VERSION "Version"

NS_ :

BS_:

BU_: Tester CCU ADC CCU_CCURT1 CCU_CCURT2 RLR RRR ZCUF ZCUL ZCUR ZCUT EMS IDM DCDC IPS NIDU NIDUF DCUR OBC OPC LPC CPC EMCM GCU DCUF IPU BMS EOPF EOPR EVCC DCDC2 EDL SRS ECS EPS EPB RBM IBCS ICM IID IDC PHUDD AMP WHUD IMR INU IFC FAPA PAS PCS SCMR SCMRL SCMRR HVSMR SCMRM MFS WSM DRM IDU FCP LBMSAD AVAS ATSS DLPFL FBLCM FLISD FLLCM FRLCM RLLCMA RLLCMB RRLCMA RRLCMB RLISD DLPML DLPMR TRM PSDL PSDR HVSPRL HVSPRR RFR SBM WCM ETC TBOX2 TBOX IDUR CBM PLGM TMC LPC2 SCMT RCP RRISD LBMS RLBMS CCURT1 CCURT2 RT1_C1 RT2_C3 RT1_C0 OTAWL RAS EBB RCICP WCMFR WCMRL SAS CD

BO_ 704 CCU_IPS_1: 64 CCU
 SG_ IPS_1_CRC : 7|16@0+ (1,0) [0|65535] ""  BMS,ADC
 SG_ IPS_1_Counter : 23|8@0+ (1,0) [0|255] ""  BMS,ADC
 SG_ IPS_DCDCModeSt : 39|3@0+ (1,0) [0|7] ""  ADC

BO_ 794 CCU_LBMSAD_1: 64 CCU
 SG_ LBMSAD_1_CRC : 7|16@0+ (1,0) [0|65535] ""  ADC,LBMS
 SG_ LBMSAD_1_Counter : 23|8@0+ (1,0) [0|255] ""  ADC,LBMS
 SG_ LBMSAD_SOFVD : 28|1@0+ (1,0) [0|1] ""  ADC,LBMS
 SG_ LBMSAD_SOFEN : 30|2@0+ (1,0) [0|3] ""  ADC,LBMS

BO_ 958 CCU_TMC_4_New: 64 CCU
 SG_ HVACPmp_MotWPSt : 401|2@0+ (1,0) [0|3] ""  ZCUL,EMS,NIDU,DCUR,DCUF,IPU,BMS,IDC,ADC
 SG_ HVACPmp_MotWPErrCode : 415|20@0+ (1,0) [0|1048576] ""  NIDU,DCUR,DCUF,IPU,ADC
 SG_ HVACSns_MotorInTVD : 402|1@0+ (1,0) [0|1] ""  ZCUL,EMS,NIDU,DCUR,DCUF,IPU,BMS,IDC,ADC
 SG_ HVACSns_MotorInT : 427|9@0+ (0.5,-50) [-50|200] "degC"  ZCUL,EMS,NIDU,DCUR,DCUF,IPU,BMS,IDC,ADC
 SG_ HVACPmp_MotWPActDuty : 447|8@0+ (1,0) [0|100] "%"  ZCUL,NIDU,DCUR,DCUF,IPU,IDC,ADC

BO_ 709 TMS_5_New: 32 CCU_CCURT1
 SG_ HVAC_AutoFogFlt : 26|1@0+ (1,0) [0|1] ""  ADC
 SG_ HVAC_AutoFogSts : 27|1@0+ (1,0) [0|1] ""  ADC
 SG_ HVAC_CorrectedCabinTemp : 39|8@0+ (0.5,-40) [-40|87.5] "°C"  CCURT2,RT2_C3,TMC,ZCUL,ZCUR,IDC,ADC
 SG_ HVAC_CorrectedCabinTempVD : 28|1@0+ (1,0) [0|1] ""  CCURT2,RT2_C3,TMC,ZCUL,ZCUR,IDC,ADC
 SG_ HVAC_CorrectedExterTemp : 47|8@0+ (0.5,-40) [-40|87.5] "°C"  CCURT2,RT2_C3,OTAWL,TMC,ZCUL,ZCUR,EMS,IPS,NIDU,NIDUF,DCUR,OBC,GCU,DCUF,IPU,BMS,ECS,IBCS,IID,IDC,AMP,ADC,IFC,PAS,WSM
 SG_ HVAC_CorrectedExterTempFault : 30|2@0+ (1,0) [0|3] ""  CCURT2,RT2_C3,OTAWL,TMC,ZCUL,ZCUR,EMS,IPS,NIDU,NIDUF,DCUR,OBC,GCU,DCUF,IPU,BMS,ECS,IBCS,IID,IDC,AMP,ADC,IFC,PAS,WSM
 SG_ HVAC_CorrectedExterTempVD : 31|1@0+ (1,0) [0|1] ""  CCURT2,RT2_C3,OTAWL,TMC,ZCUL,ZCUR,EMS,IPS,NIDU,NIDUF,DCUR,OBC,GCU,DCUF,IPU,BMS,ECS,IBCS,IID,IDC,AMP,ADC,IFC,PAS,WSM
 SG_ HVAC_MotWtrPmpSt : 51|2@0+ (1,0) [0|3] ""  TMC,ZCUL,ZCUR,EMS,NIDU,NIDUF,DCUR,DCUF,IPU,IDC,ADC,FCP
 SG_ HVAC_RearDefrostSt : 116|1@0+ (1,0) [0|1] ""  ZCUL,ZCUR,IDC,RCICP,AMP,ADC,IFC,FCP,RCP,HVSPRL,HVSPRR
 SG_ HVAC_WindExitMode : 122|3@0+ (1,0) [0|7] ""  ZCUL,ZCUR,EMS,IDC,ADC,IFC

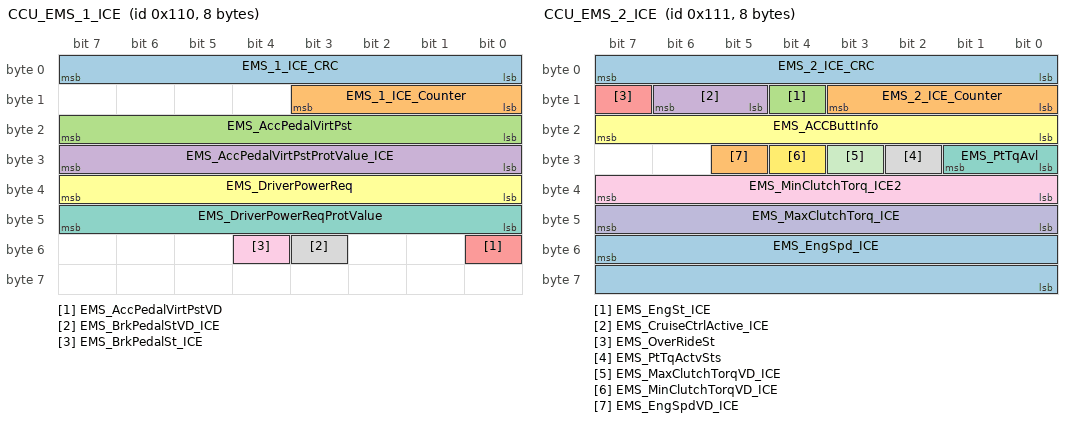
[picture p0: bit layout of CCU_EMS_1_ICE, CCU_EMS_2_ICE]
BO_ 272 CCU_EMS_1_ICE: 8 CCU
 SG_ EMS_1_ICE_CRC : 7|8@0+ (1,0) [0|255] ""  ADC
 SG_ EMS_1_ICE_Counter : 11|4@0+ (1,0) [0|14] ""  ADC
 SG_ EMS_AccPedalVirtPst : 23|8@0+ (0.392,0) [0|99.96] "%"  ADC
 SG_ EMS_AccPedalVirtPstProtValue_ICE : 31|8@0+ (1,0) [0|255] ""  ADC
 SG_ EMS_AccPedalVirtPstVD : 48|1@0+ (1,0) [0|1] ""  ADC
 SG_ EMS_DriverPowerReq : 39|8@0+ (0.78125,0) [0|198.4375] "Kw"  ADC
 SG_ EMS_DriverPowerReqProtValue : 47|8@0+ (1,0) [0|255] ""  ADC
 SG_ EMS_BrkPedalStVD_ICE : 51|1@0+ (1,0) [0|1] ""  ADC
 SG_ EMS_BrkPedalSt_ICE : 52|1@0+ (1,0) [0|1] ""  ADC

BO_ 273 CCU_EMS_2_ICE: 8 CCU
 SG_ EMS_2_ICE_CRC : 7|8@0+ (1,0) [0|255] ""  ADC
 SG_ EMS_2_ICE_Counter : 11|4@0+ (1,0) [0|14] ""  ADC
 SG_ EMS_EngSt_ICE : 12|1@0+ (1,0) [0|1] ""  ADC
 SG_ EMS_CruiseCtrlActive_ICE : 14|2@0+ (1,0) [0|3] ""  ADC
 SG_ EMS_OverRideSt : 15|1@0+ (1,0) [0|1] ""  ADC
 SG_ EMS_ACCButtInfo : 23|8@0+ (1,0) [0|255] ""  ADC
 SG_ EMS_PtTqAvl : 25|2@0+ (1,0) [0|3] ""  ADC
 SG_ EMS_PtTqActvSts : 26|1@0+ (1,0) [0|1] ""  ADC
 SG_ EMS_MinClutchTorq_ICE2 : 39|8@0+ (2,-90) [-90|420] "Nm"  ADC
 SG_ EMS_MaxClutchTorq_ICE : 47|8@0+ (2,-90) [-90|420] "Nm"  ADC
 SG_ EMS_MaxClutchTorqVD_ICE : 27|1@0+ (1,0) [0|1] ""  ADC
 SG_ EMS_MinClutchTorqVD_ICE : 28|1@0+ (1,0) [0|1] ""  ADC
 SG_ EMS_EngSpd_ICE : 55|16@0+ (1,0) [0|65535] "rpm"  ADC
 SG_ EMS_EngSpdVD_ICE : 29|1@0+ (1,0) [0|1] ""  ADC

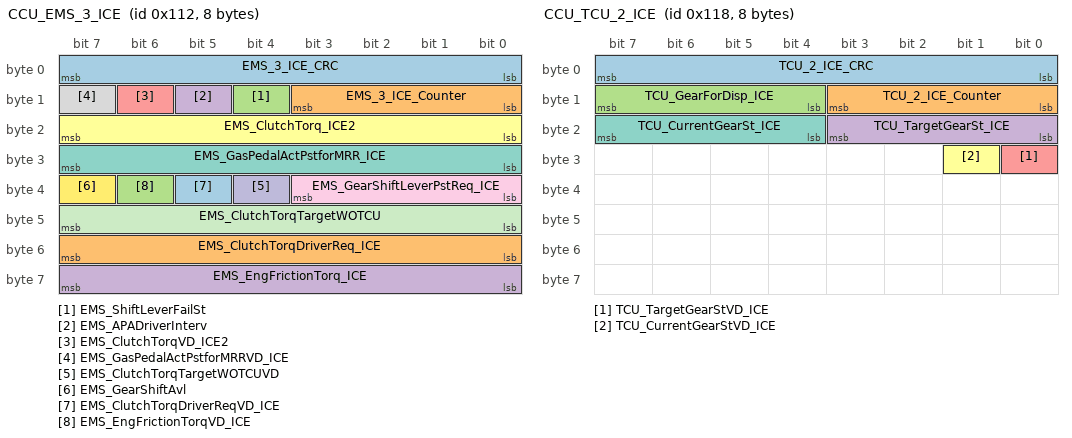
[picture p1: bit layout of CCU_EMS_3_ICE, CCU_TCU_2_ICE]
BO_ 274 CCU_EMS_3_ICE: 8 CCU
 SG_ EMS_3_ICE_CRC : 7|8@0+ (1,0) [0|255] ""  ZCUL,ZCUR,ADC
 SG_ EMS_3_ICE_Counter : 11|4@0+ (1,0) [0|14] ""  ZCUL,ZCUR,ADC
 SG_ EMS_ShiftLeverFailSt : 12|1@0+ (1,0) [0|1] ""  ADC
 SG_ EMS_APADriverInterv : 13|1@0+ (1,0) [0|1] ""  ADC
 SG_ EMS_ClutchTorqVD_ICE2 : 14|1@0+ (1,0) [0|1] ""  ZCUL,ZCUR,ADC
 SG_ EMS_ClutchTorq_ICE2 : 23|8@0+ (2,-90) [-90|420] "Nm"  ZCUL,ZCUR,ADC
 SG_ EMS_GasPedalActPstforMRR_ICE : 31|8@0+ (0.392,0) [0|99.96] "%"  ZCUL,ZCUR,ADC
 SG_ EMS_GasPedalActPstforMRRVD_ICE : 15|1@0+ (1,0) [0|1] ""  ZCUL,ZCUR,ADC
 SG_ EMS_GearShiftLeverPstReq_ICE : 35|4@0+ (1,0) [0|15] ""  ZCUL,ZCUR,ADC
 SG_ EMS_ClutchTorqTargetWOTCUVD : 36|1@0+ (1,0) [0|1] ""  ADC
 SG_ EMS_ClutchTorqTargetWOTCU : 47|8@0+ (2,-90) [-90|420] "Nm"  ADC
 SG_ EMS_GearShiftAvl : 39|1@0+ (1,0) [0|1] ""  ADC
 SG_ EMS_ClutchTorqDriverReqVD_ICE : 37|1@0+ (1,0) [0|1] ""  ADC
 SG_ EMS_ClutchTorqDriverReq_ICE : 55|8@0+ (2,-90) [-90|420] "Nm"  ADC
 SG_ EMS_EngFrictionTorqVD_ICE : 38|1@0+ (1,0) [0|1] ""  ADC
 SG_ EMS_EngFrictionTorq_ICE : 63|8@0+ (2,-90) [-90|420] "Nm"  ADC

BO_ 280 CCU_TCU_2_ICE: 8 CCU
 SG_ TCU_2_ICE_CRC : 7|8@0+ (1,0) [0|255] ""  ZCUL,ZCUR,ADC
 SG_ TCU_2_ICE_Counter : 11|4@0+ (1,0) [0|14] ""  ZCUL,ZCUR,ADC
 SG_ TCU_GearForDisp_ICE : 15|4@0+ (1,0) [0|15] ""  ZCUL,ZCUR,ADC
 SG_ TCU_TargetGearSt_ICE : 19|4@0+ (1,0) [0|15] ""  ADC
 SG_ TCU_TargetGearStVD_ICE : 24|1@0+ (1,0) [0|1] ""  ADC
 SG_ TCU_CurrentGearStVD_ICE : 25|1@0+ (1,0) [0|1] ""  ZCUL,ZCUR,ADC
 SG_ TCU_CurrentGearSt_ICE : 23|4@0+ (1,0) [0|15] ""  ZCUL,ZCUR,ADC

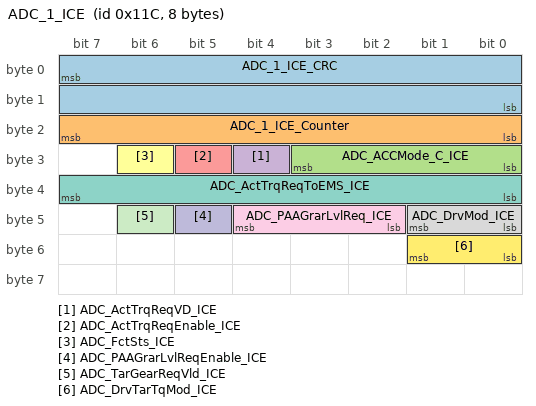
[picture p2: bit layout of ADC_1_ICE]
BO_ 284 ADC_1_ICE: 8 ADC
 SG_ ADC_1_ICE_CRC : 7|16@0+ (1,0) [0|65535] ""  CCU
 SG_ ADC_1_ICE_Counter : 23|8@0+ (1,0) [0|255] ""  CCU
 SG_ ADC_ACCMode_C_ICE : 27|4@0+ (1,0) [0|15] ""  CCU
 SG_ ADC_ActTrqReqVD_ICE : 28|1@0+ (1,0) [0|1] ""  CCU
 SG_ ADC_ActTrqReqEnable_ICE : 29|1@0+ (1,0) [0|1] ""  CCU
 SG_ ADC_FctSts_ICE : 30|1@0+ (1,0) [0|1] ""  CCU
 SG_ ADC_ActTrqReqToEMS_ICE : 39|8@0+ (2,0) [-90|420] ""  CCU
 SG_ ADC_DrvMod_ICE : 41|2@0+ (1,0) [0|3] ""  CCU
 SG_ ADC_PAAGrarLvlReq_ICE : 44|3@0+ (1,0) [0|7] ""  CCU
 SG_ ADC_PAAGrarLvlReqEnable_ICE : 45|1@0+ (1,0) [0|1] ""  CCU
 SG_ ADC_TarGearReqVld_ICE : 46|1@0+ (1,0) [0|1] ""  CCU
 SG_ ADC_DrvTarTqMod_ICE : 49|2@0+ (1,0) [0|3] ""  CCU

BO_ 1174 ADC_BigData: 64 ADC
 SG_ ADC_BigData : 7|512@0+ (1,0) [0|1] ""  CCU

CM_ SG_ 704 IPS_1_CRC "E2E Profile 5 CRC";
CM_ SG_ 704 IPS_1_Counter "E2E Profile 5 Counter";
CM_ SG_ 704 IPS_DCDCModeSt "mode status of DCDC";
CM_ SG_ 794 LBMSAD_1_CRC "E2E Profile 5 CRC";
CM_ SG_ 794 LBMSAD_1_Counter "E2E Profile 5 Counter";
CM_ SG_ 794 LBMSAD_SOFVD "LBMSAD Validity of SOF";
CM_ SG_ 794 LBMSAD_SOFEN "LBMSAD  State of Function Enable";
CM_ SG_ 958 HVACPmp_MotWPSt " motor  Water Pump State";
CM_ SG_ 958 HVACPmp_MotWPErrCode " motor  Water Pump fault";
CM_ SG_ 958 HVACSns_MotorInTVD " Motor Inlet water temperature valid flag";
CM_ SG_ 958 HVACSns_MotorInT " Motor Inlet water temperature";
CM_ SG_ 958 HVACPmp_MotWPActDuty "  motor Water Pump duty feedback";
CM_ SG_ 709 HVAC_AutoFogFlt "Auto Fog Function Fault Flag";
CM_ SG_ 709 HVAC_AutoFogSts "Auto Fog Function Status";
CM_ SG_ 709 HVAC_CorrectedCabinTemp "Corrected cabin temperature";
CM_ SG_ 709 HVAC_CorrectedCabinTempVD "Signal CorrectedCabinTemp validity";
CM_ SG_ 709 HVAC_CorrectedExterTemp "Corrected External temperature";
CM_ SG_ 709 HVAC_CorrectedExterTempFault "ExterTemp Fault Status";
CM_ SG_ 709 HVAC_CorrectedExterTempVD "External temperature valid data";
CM_ SG_ 709 HVAC_MotWtrPmpSt " motor Water Pump fault";
CM_ SG_ 709 HVAC_RearDefrostSt "Rear window and mirror heater activation status";
CM_ SG_ 709 HVAC_WindExitMode "The wind exit mode";
CM_ SG_ 272 EMS_1_ICE_CRC "E2E Profile Variant 1A CRC";
CM_ SG_ 272 EMS_1_ICE_Counter "E2E Profile Variant 1A Counter";
CM_ SG_ 272 EMS_AccPedalVirtPst "Current virtual accelerate pedal position";
CM_ SG_ 272 EMS_AccPedalVirtPstProtValue_ICE "Current virtual accelerate pedal actual position  protect value";
CM_ SG_ 272 EMS_AccPedalVirtPstVD "Current virtual accelerate pedal actual position validity";
CM_ SG_ 272 EMS_DriverPowerReq "It is the engine power set-point calculated in normal running conditions or during gearshift";
CM_ SG_ 272 EMS_DriverPowerReqProtValue "Signal\"EMS_DriverPowerReq\" protect value";
CM_ SG_ 272 EMS_BrkPedalStVD_ICE "EMS_BrkPedalSt valid data";
CM_ SG_ 272 EMS_BrkPedalSt_ICE "Brake pedal status";
CM_ SG_ 273 EMS_2_ICE_CRC "E2E Profile Variant 1A CRC";
CM_ SG_ 273 EMS_2_ICE_Counter "E2E Profile Variant 1A Counter";
CM_ SG_ 273 EMS_EngSt_ICE "Engine running status";
CM_ SG_ 273 EMS_CruiseCtrlActive_ICE "Cruise Control Active for display";
CM_ SG_ 273 EMS_OverRideSt "Indicate driver's need for acceration is bigger than virtual acceration  while in cruise mode";
CM_ SG_ 273 EMS_ACCButtInfo "ACC Button Information";
CM_ SG_ 273 EMS_PtTqAvl "EMS system available state";
CM_ SG_ 273 EMS_PtTqActvSts "EMS torue response state";
CM_ SG_ 273 EMS_MinClutchTorq_ICE2 "Minimum clutch input Torque";
CM_ SG_ 273 EMS_MaxClutchTorq_ICE "Maximum clutch input torque that would be available at current engine speed, current enviromental conditions.It takes into account possible limitations.";
CM_ SG_ 273 EMS_MaxClutchTorqVD_ICE "Maximum Clutch Torque Valid Data";
CM_ SG_ 273 EMS_MinClutchTorqVD_ICE "Minimum Clutch Torque Valid Data";
CM_ SG_ 273 EMS_EngSpd_ICE "Engine Speed";
CM_ SG_ 273 EMS_EngSpdVD_ICE "\"EMS_EngSpd\" valid data";
CM_ SG_ 274 EMS_3_ICE_CRC "E2E Profile Variant 1A CRC";
CM_ SG_ 274 EMS_3_ICE_Counter "E2E Profile Variant 1A Counter";
CM_ SG_ 274 EMS_ShiftLeverFailSt "Shift lever failed status indication";
CM_ SG_ 274 EMS_APADriverInterv "GSM_APADriverInterv";
CM_ SG_ 274 EMS_ClutchTorqVD_ICE2 "EMS_ClutchTorq statusvalid data";
CM_ SG_ 274 EMS_ClutchTorq_ICE2 "Current clutch input torque";
CM_ SG_ 274 EMS_GasPedalActPstforMRR_ICE "Current actual accelerate pedal position";
CM_ SG_ 274 EMS_GasPedalActPstforMRRVD_ICE "Current actual accelerate pedal position Valid Data";
CM_ SG_ 274 EMS_GearShiftLeverPstReq_ICE "Gear shift lever postion request";
CM_ SG_ 274 EMS_ClutchTorqTargetWOTCUVD "\"EMS_ClutchTorqTargetWOTCU\" Valid Data";
CM_ SG_ 274 EMS_ClutchTorqTargetWOTCU "Target clutch input Torque without TCU intervention";
CM_ SG_ 274 EMS_GearShiftAvl "Gear Shift Available status";
CM_ SG_ 274 EMS_ClutchTorqDriverReqVD_ICE "\"EMS_ClutchTorqDriverReq\" valid data";
CM_ SG_ 274 EMS_ClutchTorqDriverReq_ICE "Clutch input torque requested by driver or cruise control";
CM_ SG_ 274 EMS_EngFrictionTorqVD_ICE "\"EMS_EngFrictionTorq\" valid data";
CM_ SG_ 274 EMS_EngFrictionTorq_ICE "Torque losses caused by engine mechanical losses，gas change and torque demands of auxiliary loads";
CM_ SG_ 280 TCU_2_ICE_CRC "E2E Profile Variant 1A CRC";
CM_ SG_ 280 TCU_2_ICE_Counter "E2E Profile Variant 1A Counter";
CM_ SG_ 280 TCU_GearForDisp_ICE "Gear lever for display";
CM_ SG_ 280 TCU_TargetGearSt_ICE "Target gear";
CM_ SG_ 280 TCU_TargetGearStVD_ICE "Target gear valid data";
CM_ SG_ 280 TCU_CurrentGearStVD_ICE "Current gear valid data";
CM_ SG_ 280 TCU_CurrentGearSt_ICE "Current gear";
CM_ SG_ 284 ADC_1_ICE_CRC "E2E Profile 5 CRC";
CM_ SG_ 284 ADC_1_ICE_Counter "E2E Profile 5 Counter";
CM_ SG_ 284 ADC_ACCMode_C_ICE "This signal indicates ACC(Adaptive cruise control)status";
CM_ SG_ 284 ADC_ActTrqReqVD_ICE "The validity of ADC torque request";
CM_ SG_ 284 ADC_ActTrqReqEnable_ICE "Enable flag for realization of target torque ActTrqReq";
CM_ SG_ 284 ADC_FctSts_ICE "ADAS active status";
CM_ SG_ 284 ADC_ActTrqReqToEMS_ICE "VLC Request Effective target torque on Clutch level to EMS";
CM_ SG_ 284 ADC_DrvMod_ICE "This signal indicates which function the total target  torque is used for，cruise or parking function.";
CM_ SG_ 284 ADC_PAAGrarLvlReq_ICE "Gear lever position request for the vehicle mo-tion control";
CM_ SG_ 284 ADC_PAAGrarLvlReqEnable_ICE "enable flag to control the gear box";
CM_ SG_ 284 ADC_TarGearReqVld_ICE "Gear lever request validity";
CM_ SG_ 284 ADC_DrvTarTqMod_ICE "Drive torque mode:Override mode or Inhibit mode";

BA_DEF_ BO_  "GenMsgCycleTime" INT 0 0;
BA_DEF_ BO_  "GenMsgCycleTimeFast" INT 0 0;
BA_DEF_ BO_  "GenMsgSendType" ENUM  "Periodic","Event","IfActive","POE","PA","FixedPeriodic","Event","EnabledPeriodic","NotUsed","NotUsed","EventPeriodic","NotUsed","NotUsed","NoMsgSendType";
BA_DEF_ BO_  "VFrameFormat" ENUM  "StandardCAN","ExtendedCAN","reserved","reserved","reserved","reserved","reserved","reserved","reserved","reserved","reserved","reserved","reserved","reserved","StandardCAN_FD","ExtendedCAN_FD";
BA_DEF_ BO_  "CANFD_BRS" ENUM  "0","1";
BA_DEF_ SG_  "EventCommandSignal" ENUM  "No","Yes";
BA_DEF_ SG_  "GatewayedSignals" ENUM  "No","Yes";
BA_DEF_ SG_  "GenSigInactiveValue" HEX 0 0;
BA_DEF_ SG_  "GenSigInvalidValue" HEX 0 0;
BA_DEF_ SG_  "GenSigSendType" ENUM  "Trigger","Passive","Cyclic","OnWrite","OnWriteWithRepetition","OnChange","OnChangeWithRepetition","IfActive","IfActiveWithRepetition","NoSigSendType";
BA_DEF_ SG_  "GenSigStartValue" HEX 0 0;
BA_DEF_ SG_  "GenSigTimeoutValue" HEX 0 0;
BA_DEF_ SG_  "Remark" STRING ;
BA_ "GenMsgCycleTime" BO_ 704 20;
BA_ "GenMsgCycleTimeFast" BO_ 704 0;
BA_ "GenMsgSendType" BO_ 704 0;
BA_ "VFrameFormat" BO_ 704 14;
BA_ "CANFD_BRS" BO_ 704 1;
BA_ "GenMsgCycleTime" BO_ 704 20;
BA_ "GenMsgCycleTimeFast" BO_ 704 0;
BA_ "GenMsgSendType" BO_ 704 0;
BA_ "VFrameFormat" BO_ 704 14;
BA_ "CANFD_BRS" BO_ 704 1;
BA_ "GenMsgCycleTime" BO_ 704 20;
BA_ "GenMsgCycleTimeFast" BO_ 704 0;
BA_ "GenMsgSendType" BO_ 704 0;
BA_ "VFrameFormat" BO_ 704 14;
BA_ "CANFD_BRS" BO_ 704 1;
BA_ "GenMsgCycleTime" BO_ 794 100;
BA_ "GenMsgCycleTimeFast" BO_ 794 0;
BA_ "GenMsgSendType" BO_ 794 0;
BA_ "VFrameFormat" BO_ 794 14;
BA_ "CANFD_BRS" BO_ 794 1;
BA_ "GenMsgCycleTime" BO_ 794 100;
BA_ "GenMsgCycleTimeFast" BO_ 794 0;
BA_ "GenMsgSendType" BO_ 794 0;
BA_ "VFrameFormat" BO_ 794 14;
BA_ "CANFD_BRS" BO_ 794 1;
BA_ "GenMsgCycleTime" BO_ 794 100;
BA_ "GenMsgCycleTimeFast" BO_ 794 0;
BA_ "GenMsgSendType" BO_ 794 0;
BA_ "VFrameFormat" BO_ 794 14;
BA_ "CANFD_BRS" BO_ 794 1;
BA_ "GenMsgCycleTime" BO_ 794 100;
BA_ "GenMsgCycleTimeFast" BO_ 794 0;
BA_ "GenMsgSendType" BO_ 794 0;
BA_ "VFrameFormat" BO_ 794 14;
BA_ "CANFD_BRS" BO_ 794 1;
BA_ "GenMsgCycleTime" BO_ 958 200;
BA_ "GenMsgCycleTimeFast" BO_ 958 0;
BA_ "GenMsgSendType" BO_ 958 0;
BA_ "VFrameFormat" BO_ 958 14;
BA_ "CANFD_BRS" BO_ 958 1;
BA_ "GenMsgCycleTime" BO_ 958 200;
BA_ "GenMsgCycleTimeFast" BO_ 958 0;
BA_ "GenMsgSendType" BO_ 958 0;
BA_ "VFrameFormat" BO_ 958 14;
BA_ "CANFD_BRS" BO_ 958 1;
BA_ "GenMsgCycleTime" BO_ 958 200;
BA_ "GenMsgCycleTimeFast" BO_ 958 0;
BA_ "GenMsgSendType" BO_ 958 0;
BA_ "VFrameFormat" BO_ 958 14;
BA_ "CANFD_BRS" BO_ 958 1;
BA_ "GenMsgCycleTime" BO_ 958 200;
BA_ "GenMsgCycleTimeFast" BO_ 958 0;
BA_ "GenMsgSendType" BO_ 958 0;
BA_ "VFrameFormat" BO_ 958 14;
BA_ "CANFD_BRS" BO_ 958 1;
BA_ "GenMsgCycleTime" BO_ 958 200;
BA_ "GenMsgCycleTimeFast" BO_ 958 0;
BA_ "GenMsgSendType" BO_ 958 0;
BA_ "VFrameFormat" BO_ 958 14;
BA_ "CANFD_BRS" BO_ 958 1;
BA_ "GenMsgCycleTime" BO_ 709 100;
BA_ "GenMsgCycleTimeFast" BO_ 709 0;
BA_ "GenMsgSendType" BO_ 709 0;
BA_ "VFrameFormat" BO_ 709 14;
BA_ "CANFD_BRS" BO_ 709 1;
BA_ "GenMsgCycleTime" BO_ 709 100;
BA_ "GenMsgCycleTimeFast" BO_ 709 0;
BA_ "GenMsgSendType" BO_ 709 0;
BA_ "VFrameFormat" BO_ 709 14;
BA_ "CANFD_BRS" BO_ 709 1;
BA_ "GenMsgCycleTime" BO_ 709 100;
BA_ "GenMsgCycleTimeFast" BO_ 709 0;
BA_ "GenMsgSendType" BO_ 709 0;
BA_ "VFrameFormat" BO_ 709 14;
BA_ "CANFD_BRS" BO_ 709 1;
BA_ "GenMsgCycleTime" BO_ 709 100;
BA_ "GenMsgCycleTimeFast" BO_ 709 0;
BA_ "GenMsgSendType" BO_ 709 0;
BA_ "VFrameFormat" BO_ 709 14;
BA_ "CANFD_BRS" BO_ 709 1;
BA_ "GenMsgCycleTime" BO_ 709 100;
BA_ "GenMsgCycleTimeFast" BO_ 709 0;
BA_ "GenMsgSendType" BO_ 709 0;
BA_ "VFrameFormat" BO_ 709 14;
BA_ "CANFD_BRS" BO_ 709 1;
BA_ "GenMsgCycleTime" BO_ 709 100;
BA_ "GenMsgCycleTimeFast" BO_ 709 0;
BA_ "GenMsgSendType" BO_ 709 0;
BA_ "VFrameFormat" BO_ 709 14;
BA_ "CANFD_BRS" BO_ 709 1;
BA_ "GenMsgCycleTime" BO_ 709 100;
BA_ "GenMsgCycleTimeFast" BO_ 709 0;
BA_ "GenMsgSendType" BO_ 709 0;
BA_ "VFrameFormat" BO_ 709 14;
BA_ "CANFD_BRS" BO_ 709 1;
BA_ "GenMsgCycleTime" BO_ 709 100;
BA_ "GenMsgCycleTimeFast" BO_ 709 0;
BA_ "GenMsgSendType" BO_ 709 0;
BA_ "VFrameFormat" BO_ 709 14;
BA_ "CANFD_BRS" BO_ 709 1;
BA_ "GenMsgCycleTime" BO_ 709 100;
BA_ "GenMsgCycleTimeFast" BO_ 709 0;
BA_ "GenMsgSendType" BO_ 709 0;
BA_ "VFrameFormat" BO_ 709 14;
BA_ "CANFD_BRS" BO_ 709 1;
BA_ "GenMsgCycleTime" BO_ 709 100;
BA_ "GenMsgCycleTimeFast" BO_ 709 0;
BA_ "GenMsgSendType" BO_ 709 0;
BA_ "VFrameFormat" BO_ 709 14;
BA_ "CANFD_BRS" BO_ 709 1;
BA_ "GenMsgCycleTime" BO_ 272 10;
BA_ "GenMsgCycleTimeFast" BO_ 272 0;
BA_ "GenMsgSendType" BO_ 272 0;
BA_ "VFrameFormat" BO_ 272 14;
BA_ "CANFD_BRS" BO_ 272 1;
BA_ "GenMsgCycleTime" BO_ 272 10;
BA_ "GenMsgCycleTimeFast" BO_ 272 0;
BA_ "GenMsgSendType" BO_ 272 0;
BA_ "VFrameFormat" BO_ 272 14;
BA_ "CANFD_BRS" BO_ 272 1;
BA_ "GenMsgCycleTime" BO_ 272 10;
BA_ "GenMsgCycleTimeFast" BO_ 272 0;
BA_ "GenMsgSendType" BO_ 272 0;
BA_ "VFrameFormat" BO_ 272 14;
BA_ "CANFD_BRS" BO_ 272 1;
BA_ "GenMsgCycleTime" BO_ 272 10;
BA_ "GenMsgCycleTimeFast" BO_ 272 0;
BA_ "GenMsgSendType" BO_ 272 0;
BA_ "VFrameFormat" BO_ 272 14;
BA_ "CANFD_BRS" BO_ 272 1;
BA_ "GenMsgCycleTime" BO_ 272 10;
BA_ "GenMsgCycleTimeFast" BO_ 272 0;
BA_ "GenMsgSendType" BO_ 272 0;
BA_ "VFrameFormat" BO_ 272 14;
BA_ "CANFD_BRS" BO_ 272 1;
BA_ "GenMsgCycleTime" BO_ 272 10;
BA_ "GenMsgCycleTimeFast" BO_ 272 0;
BA_ "GenMsgSendType" BO_ 272 0;
BA_ "VFrameFormat" BO_ 272 14;
BA_ "CANFD_BRS" BO_ 272 1;
BA_ "GenMsgCycleTime" BO_ 272 10;
BA_ "GenMsgCycleTimeFast" BO_ 272 0;
BA_ "GenMsgSendType" BO_ 272 0;
BA_ "VFrameFormat" BO_ 272 14;
BA_ "CANFD_BRS" BO_ 272 1;
BA_ "GenMsgCycleTime" BO_ 272 10;
BA_ "GenMsgCycleTimeFast" BO_ 272 0;
BA_ "GenMsgSendType" BO_ 272 0;
BA_ "VFrameFormat" BO_ 272 14;
BA_ "CANFD_BRS" BO_ 272 1;
BA_ "GenMsgCycleTime" BO_ 272 10;
BA_ "GenMsgCycleTimeFast" BO_ 272 0;
BA_ "GenMsgSendType" BO_ 272 0;
BA_ "VFrameFormat" BO_ 272 14;
BA_ "CANFD_BRS" BO_ 272 1;
BA_ "GenMsgCycleTime" BO_ 273 10;
BA_ "GenMsgCycleTimeFast" BO_ 273 0;
BA_ "GenMsgSendType" BO_ 273 0;
BA_ "VFrameFormat" BO_ 273 14;
BA_ "CANFD_BRS" BO_ 273 1;
BA_ "GenMsgCycleTime" BO_ 273 10;
BA_ "GenMsgCycleTimeFast" BO_ 273 0;
BA_ "GenMsgSendType" BO_ 273 0;
BA_ "VFrameFormat" BO_ 273 14;
BA_ "CANFD_BRS" BO_ 273 1;
BA_ "GenMsgCycleTime" BO_ 273 10;
BA_ "GenMsgCycleTimeFast" BO_ 273 0;
BA_ "GenMsgSendType" BO_ 273 0;
BA_ "VFrameFormat" BO_ 273 14;
BA_ "CANFD_BRS" BO_ 273 1;
BA_ "GenMsgCycleTime" BO_ 273 10;
BA_ "GenMsgCycleTimeFast" BO_ 273 0;
BA_ "GenMsgSendType" BO_ 273 0;
BA_ "VFrameFormat" BO_ 273 14;
BA_ "CANFD_BRS" BO_ 273 1;
BA_ "GenMsgCycleTime" BO_ 273 10;
BA_ "GenMsgCycleTimeFast" BO_ 273 0;
BA_ "GenMsgSendType" BO_ 273 0;
BA_ "VFrameFormat" BO_ 273 14;
BA_ "CANFD_BRS" BO_ 273 1;
BA_ "GenMsgCycleTime" BO_ 273 10;
BA_ "GenMsgCycleTimeFast" BO_ 273 0;
BA_ "GenMsgSendType" BO_ 273 0;
BA_ "VFrameFormat" BO_ 273 14;
BA_ "CANFD_BRS" BO_ 273 1;
BA_ "GenMsgCycleTime" BO_ 273 10;
BA_ "GenMsgCycleTimeFast" BO_ 273 0;
BA_ "GenMsgSendType" BO_ 273 0;
BA_ "VFrameFormat" BO_ 273 14;
BA_ "CANFD_BRS" BO_ 273 1;
BA_ "GenMsgCycleTime" BO_ 273 10;
BA_ "GenMsgCycleTimeFast" BO_ 273 0;
BA_ "GenMsgSendType" BO_ 273 0;
BA_ "VFrameFormat" BO_ 273 14;
BA_ "CANFD_BRS" BO_ 273 1;
BA_ "GenMsgCycleTime" BO_ 273 10;
BA_ "GenMsgCycleTimeFast" BO_ 273 0;
BA_ "GenMsgSendType" BO_ 273 0;
BA_ "VFrameFormat" BO_ 273 14;
BA_ "CANFD_BRS" BO_ 273 1;
BA_ "GenMsgCycleTime" BO_ 273 10;
BA_ "GenMsgCycleTimeFast" BO_ 273 0;
BA_ "GenMsgSendType" BO_ 273 0;
BA_ "VFrameFormat" BO_ 273 14;
BA_ "CANFD_BRS" BO_ 273 1;
BA_ "GenMsgCycleTime" BO_ 273 10;
BA_ "GenMsgCycleTimeFast" BO_ 273 0;
BA_ "GenMsgSendType" BO_ 273 0;
BA_ "VFrameFormat" BO_ 273 14;
BA_ "CANFD_BRS" BO_ 273 1;
BA_ "GenMsgCycleTime" BO_ 273 10;
BA_ "GenMsgCycleTimeFast" BO_ 273 0;
BA_ "GenMsgSendType" BO_ 273 0;
BA_ "VFrameFormat" BO_ 273 14;
BA_ "CANFD_BRS" BO_ 273 1;
BA_ "GenMsgCycleTime" BO_ 273 10;
BA_ "GenMsgCycleTimeFast" BO_ 273 0;
BA_ "GenMsgSendType" BO_ 273 0;
BA_ "VFrameFormat" BO_ 273 14;
BA_ "CANFD_BRS" BO_ 273 1;
BA_ "GenMsgCycleTime" BO_ 273 10;
BA_ "GenMsgCycleTimeFast" BO_ 273 0;
BA_ "GenMsgSendType" BO_ 273 0;
BA_ "VFrameFormat" BO_ 273 14;
BA_ "CANFD_BRS" BO_ 273 1;
BA_ "GenMsgCycleTime" BO_ 274 10;
BA_ "GenMsgCycleTimeFast" BO_ 274 0;
BA_ "GenMsgSendType" BO_ 274 0;
BA_ "VFrameFormat" BO_ 274 14;
BA_ "CANFD_BRS" BO_ 274 1;
BA_ "GenMsgCycleTime" BO_ 274 10;
BA_ "GenMsgCycleTimeFast" BO_ 274 0;
BA_ "GenMsgSendType" BO_ 274 0;
BA_ "VFrameFormat" BO_ 274 14;
BA_ "CANFD_BRS" BO_ 274 1;
BA_ "GenMsgCycleTime" BO_ 274 10;
BA_ "GenMsgCycleTimeFast" BO_ 274 0;
BA_ "GenMsgSendType" BO_ 274 0;
BA_ "VFrameFormat" BO_ 274 14;
BA_ "CANFD_BRS" BO_ 274 1;
BA_ "GenMsgCycleTime" BO_ 274 10;
BA_ "GenMsgCycleTimeFast" BO_ 274 0;
BA_ "GenMsgSendType" BO_ 274 0;
BA_ "VFrameFormat" BO_ 274 14;
BA_ "CANFD_BRS" BO_ 274 1;
BA_ "GenMsgCycleTime" BO_ 274 10;
BA_ "GenMsgCycleTimeFast" BO_ 274 0;
BA_ "GenMsgSendType" BO_ 274 0;
BA_ "VFrameFormat" BO_ 274 14;
BA_ "CANFD_BRS" BO_ 274 1;
BA_ "GenMsgCycleTime" BO_ 274 10;
BA_ "GenMsgCycleTimeFast" BO_ 274 0;
BA_ "GenMsgSendType" BO_ 274 0;
BA_ "VFrameFormat" BO_ 274 14;
BA_ "CANFD_BRS" BO_ 274 1;
BA_ "GenMsgCycleTime" BO_ 274 10;
BA_ "GenMsgCycleTimeFast" BO_ 274 0;
BA_ "GenMsgSendType" BO_ 274 0;
BA_ "VFrameFormat" BO_ 274 14;
BA_ "CANFD_BRS" BO_ 274 1;
BA_ "GenMsgCycleTime" BO_ 274 10;
BA_ "GenMsgCycleTimeFast" BO_ 274 0;
BA_ "GenMsgSendType" BO_ 274 0;
BA_ "VFrameFormat" BO_ 274 14;
BA_ "CANFD_BRS" BO_ 274 1;
BA_ "GenMsgCycleTime" BO_ 274 10;
BA_ "GenMsgCycleTimeFast" BO_ 274 0;
BA_ "GenMsgSendType" BO_ 274 0;
BA_ "VFrameFormat" BO_ 274 14;
BA_ "CANFD_BRS" BO_ 274 1;
BA_ "GenMsgCycleTime" BO_ 274 10;
BA_ "GenMsgCycleTimeFast" BO_ 274 0;
BA_ "GenMsgSendType" BO_ 274 0;
BA_ "VFrameFormat" BO_ 274 14;
BA_ "CANFD_BRS" BO_ 274 1;
BA_ "GenMsgCycleTime" BO_ 274 10;
BA_ "GenMsgCycleTimeFast" BO_ 274 0;
BA_ "GenMsgSendType" BO_ 274 0;
BA_ "VFrameFormat" BO_ 274 14;
BA_ "CANFD_BRS" BO_ 274 1;
BA_ "GenMsgCycleTime" BO_ 274 10;
BA_ "GenMsgCycleTimeFast" BO_ 274 0;
BA_ "GenMsgSendType" BO_ 274 0;
BA_ "VFrameFormat" BO_ 274 14;
BA_ "CANFD_BRS" BO_ 274 1;
BA_ "GenMsgCycleTime" BO_ 274 10;
BA_ "GenMsgCycleTimeFast" BO_ 274 0;
BA_ "GenMsgSendType" BO_ 274 0;
BA_ "VFrameFormat" BO_ 274 14;
BA_ "CANFD_BRS" BO_ 274 1;
BA_ "GenMsgCycleTime" BO_ 274 10;
BA_ "GenMsgCycleTimeFast" BO_ 274 0;
BA_ "GenMsgSendType" BO_ 274 0;
BA_ "VFrameFormat" BO_ 274 14;
BA_ "CANFD_BRS" BO_ 274 1;
BA_ "GenMsgCycleTime" BO_ 274 10;
BA_ "GenMsgCycleTimeFast" BO_ 274 0;
BA_ "GenMsgSendType" BO_ 274 0;
BA_ "VFrameFormat" BO_ 274 14;
BA_ "CANFD_BRS" BO_ 274 1;
BA_ "GenMsgCycleTime" BO_ 274 10;
BA_ "GenMsgCycleTimeFast" BO_ 274 0;
BA_ "GenMsgSendType" BO_ 274 0;
BA_ "VFrameFormat" BO_ 274 14;
BA_ "CANFD_BRS" BO_ 274 1;
BA_ "GenMsgCycleTime" BO_ 280 10;
BA_ "GenMsgCycleTimeFast" BO_ 280 0;
BA_ "GenMsgSendType" BO_ 280 0;
BA_ "VFrameFormat" BO_ 280 14;
BA_ "CANFD_BRS" BO_ 280 1;
BA_ "GenMsgCycleTime" BO_ 280 10;
BA_ "GenMsgCycleTimeFast" BO_ 280 0;
BA_ "GenMsgSendType" BO_ 280 0;
BA_ "VFrameFormat" BO_ 280 14;
BA_ "CANFD_BRS" BO_ 280 1;
BA_ "GenMsgCycleTime" BO_ 280 10;
BA_ "GenMsgCycleTimeFast" BO_ 280 0;
BA_ "GenMsgSendType" BO_ 280 0;
BA_ "VFrameFormat" BO_ 280 14;
BA_ "CANFD_BRS" BO_ 280 1;
BA_ "GenMsgCycleTime" BO_ 280 10;
BA_ "GenMsgCycleTimeFast" BO_ 280 0;
BA_ "GenMsgSendType" BO_ 280 0;
BA_ "VFrameFormat" BO_ 280 14;
BA_ "CANFD_BRS" BO_ 280 1;
BA_ "GenMsgCycleTime" BO_ 280 10;
BA_ "GenMsgCycleTimeFast" BO_ 280 0;
BA_ "GenMsgSendType" BO_ 280 0;
BA_ "VFrameFormat" BO_ 280 14;
BA_ "CANFD_BRS" BO_ 280 1;
BA_ "GenMsgCycleTime" BO_ 280 10;
BA_ "GenMsgCycleTimeFast" BO_ 280 0;
BA_ "GenMsgSendType" BO_ 280 0;
BA_ "VFrameFormat" BO_ 280 14;
BA_ "CANFD_BRS" BO_ 280 1;
BA_ "GenMsgCycleTime" BO_ 280 10;
BA_ "GenMsgCycleTimeFast" BO_ 280 0;
BA_ "GenMsgSendType" BO_ 280 0;
BA_ "VFrameFormat" BO_ 280 14;
BA_ "CANFD_BRS" BO_ 280 1;
BA_ "GenMsgCycleTime" BO_ 284 10;
BA_ "GenMsgCycleTimeFast" BO_ 284 0;
BA_ "GenMsgSendType" BO_ 284 0;
BA_ "VFrameFormat" BO_ 284 14;
BA_ "CANFD_BRS" BO_ 284 1;
BA_ "GenMsgCycleTime" BO_ 284 10;
BA_ "GenMsgCycleTimeFast" BO_ 284 0;
BA_ "GenMsgSendType" BO_ 284 0;
BA_ "VFrameFormat" BO_ 284 14;
BA_ "CANFD_BRS" BO_ 284 1;
BA_ "GenMsgCycleTime" BO_ 284 10;
BA_ "GenMsgCycleTimeFast" BO_ 284 0;
BA_ "GenMsgSendType" BO_ 284 0;
BA_ "VFrameFormat" BO_ 284 14;
BA_ "CANFD_BRS" BO_ 284 1;
BA_ "GenMsgCycleTime" BO_ 284 10;
BA_ "GenMsgCycleTimeFast" BO_ 284 0;
BA_ "GenMsgSendType" BO_ 284 0;
BA_ "VFrameFormat" BO_ 284 14;
BA_ "CANFD_BRS" BO_ 284 1;
BA_ "GenMsgCycleTime" BO_ 284 10;
BA_ "GenMsgCycleTimeFast" BO_ 284 0;
BA_ "GenMsgSendType" BO_ 284 0;
BA_ "VFrameFormat" BO_ 284 14;
BA_ "CANFD_BRS" BO_ 284 1;
BA_ "GenMsgCycleTime" BO_ 284 10;
BA_ "GenMsgCycleTimeFast" BO_ 284 0;
BA_ "GenMsgSendType" BO_ 284 0;
BA_ "VFrameFormat" BO_ 284 14;
BA_ "CANFD_BRS" BO_ 284 1;
BA_ "GenMsgCycleTime" BO_ 284 10;
BA_ "GenMsgCycleTimeFast" BO_ 284 0;
BA_ "GenMsgSendType" BO_ 284 0;
BA_ "VFrameFormat" BO_ 284 14;
BA_ "CANFD_BRS" BO_ 284 1;
BA_ "GenMsgCycleTime" BO_ 284 10;
BA_ "GenMsgCycleTimeFast" BO_ 284 0;
BA_ "GenMsgSendType" BO_ 284 0;
BA_ "VFrameFormat" BO_ 284 14;
BA_ "CANFD_BRS" BO_ 284 1;
BA_ "GenMsgCycleTime" BO_ 284 10;
BA_ "GenMsgCycleTimeFast" BO_ 284 0;
BA_ "GenMsgSendType" BO_ 284 0;
BA_ "VFrameFormat" BO_ 284 14;
BA_ "CANFD_BRS" BO_ 284 1;
BA_ "GenMsgCycleTime" BO_ 284 10;
BA_ "GenMsgCycleTimeFast" BO_ 284 0;
BA_ "GenMsgSendType" BO_ 284 0;
BA_ "VFrameFormat" BO_ 284 14;
BA_ "CANFD_BRS" BO_ 284 1;
BA_ "GenMsgCycleTime" BO_ 284 10;
BA_ "GenMsgCycleTimeFast" BO_ 284 0;
BA_ "GenMsgSendType" BO_ 284 0;
BA_ "VFrameFormat" BO_ 284 14;
BA_ "CANFD_BRS" BO_ 284 1;
BA_ "GenMsgCycleTime" BO_ 284 10;
BA_ "GenMsgCycleTimeFast" BO_ 284 0;
BA_ "GenMsgSendType" BO_ 284 0;
BA_ "VFrameFormat" BO_ 284 14;
BA_ "CANFD_BRS" BO_ 284 1;
BA_ "GenMsgCycleTime" BO_ 1174 1000;
BA_ "GenMsgCycleTimeFast" BO_ 1174 0;
BA_ "GenMsgSendType" BO_ 1174 0;
BA_ "VFrameFormat" BO_ 1174 14;
BA_ "CANFD_BRS" BO_ 1174 1;
BA_ "EventCommandSignal" SG_ 704 IPS_1_CRC 0;
BA_ "GatewayedSignals" SG_ 704 IPS_1_CRC 0;
BA_ "GenSigInactiveValue" SG_ 704 IPS_1_CRC 0;
BA_ "GenSigInvalidValue" SG_ 704 IPS_1_CRC 0;
BA_ "GenSigSendType" SG_ 704 IPS_1_CRC 1;
BA_ "GenSigStartValue" SG_ 704 IPS_1_CRC 0;
BA_ "GenSigTimeoutValue" SG_ 704 IPS_1_CRC 0;
BA_ "Remark" SG_ 704 IPS_1_CRC "";
BA_ "EventCommandSignal" SG_ 704 IPS_1_Counter 0;
BA_ "GatewayedSignals" SG_ 704 IPS_1_Counter 0;
BA_ "GenSigInactiveValue" SG_ 704 IPS_1_Counter 0;
BA_ "GenSigInvalidValue" SG_ 704 IPS_1_Counter 0;
BA_ "GenSigSendType" SG_ 704 IPS_1_Counter 1;
BA_ "GenSigStartValue" SG_ 704 IPS_1_Counter 0;
BA_ "GenSigTimeoutValue" SG_ 704 IPS_1_Counter 0;
BA_ "Remark" SG_ 704 IPS_1_Counter "";
BA_ "EventCommandSignal" SG_ 704 IPS_DCDCModeSt 0;
BA_ "GatewayedSignals" SG_ 704 IPS_DCDCModeSt 0;
BA_ "GenSigInactiveValue" SG_ 704 IPS_DCDCModeSt 0;
BA_ "GenSigInvalidValue" SG_ 704 IPS_DCDCModeSt 0;
BA_ "GenSigSendType" SG_ 704 IPS_DCDCModeSt 1;
BA_ "GenSigStartValue" SG_ 704 IPS_DCDCModeSt 0;
BA_ "GenSigTimeoutValue" SG_ 704 IPS_DCDCModeSt 0;
BA_ "Remark" SG_ 704 IPS_DCDCModeSt "";
BA_ "EventCommandSignal" SG_ 794 LBMSAD_1_CRC 0;
BA_ "GatewayedSignals" SG_ 794 LBMSAD_1_CRC 0;
BA_ "GenSigInactiveValue" SG_ 794 LBMSAD_1_CRC 0;
BA_ "GenSigInvalidValue" SG_ 794 LBMSAD_1_CRC 0;
BA_ "GenSigSendType" SG_ 794 LBMSAD_1_CRC 1;
BA_ "GenSigStartValue" SG_ 794 LBMSAD_1_CRC 0;
BA_ "GenSigTimeoutValue" SG_ 794 LBMSAD_1_CRC 0;
BA_ "Remark" SG_ 794 LBMSAD_1_CRC "";
BA_ "EventCommandSignal" SG_ 794 LBMSAD_1_Counter 0;
BA_ "GatewayedSignals" SG_ 794 LBMSAD_1_Counter 0;
BA_ "GenSigInactiveValue" SG_ 794 LBMSAD_1_Counter 0;
BA_ "GenSigInvalidValue" SG_ 794 LBMSAD_1_Counter 0;
BA_ "GenSigSendType" SG_ 794 LBMSAD_1_Counter 1;
BA_ "GenSigStartValue" SG_ 794 LBMSAD_1_Counter 0;
BA_ "GenSigTimeoutValue" SG_ 794 LBMSAD_1_Counter 0;
BA_ "Remark" SG_ 794 LBMSAD_1_Counter "";
BA_ "EventCommandSignal" SG_ 794 LBMSAD_SOFVD 0;
BA_ "GatewayedSignals" SG_ 794 LBMSAD_SOFVD 0;
BA_ "GenSigInactiveValue" SG_ 794 LBMSAD_SOFVD 0;
BA_ "GenSigInvalidValue" SG_ 794 LBMSAD_SOFVD 0;
BA_ "GenSigSendType" SG_ 794 LBMSAD_SOFVD 1;
BA_ "GenSigStartValue" SG_ 794 LBMSAD_SOFVD 0;
BA_ "GenSigTimeoutValue" SG_ 794 LBMSAD_SOFVD 0;
BA_ "Remark" SG_ 794 LBMSAD_SOFVD "";
BA_ "EventCommandSignal" SG_ 794 LBMSAD_SOFEN 0;
BA_ "GatewayedSignals" SG_ 794 LBMSAD_SOFEN 0;
BA_ "GenSigInactiveValue" SG_ 794 LBMSAD_SOFEN 0;
BA_ "GenSigInvalidValue" SG_ 794 LBMSAD_SOFEN 0;
BA_ "GenSigSendType" SG_ 794 LBMSAD_SOFEN 1;
BA_ "GenSigStartValue" SG_ 794 LBMSAD_SOFEN 0;
BA_ "GenSigTimeoutValue" SG_ 794 LBMSAD_SOFEN 0;
BA_ "Remark" SG_ 794 LBMSAD_SOFEN "";
BA_ "EventCommandSignal" SG_ 958 HVACPmp_MotWPSt 0;
BA_ "GatewayedSignals" SG_ 958 HVACPmp_MotWPSt 0;
BA_ "GenSigInactiveValue" SG_ 958 HVACPmp_MotWPSt 0;
BA_ "GenSigInvalidValue" SG_ 958 HVACPmp_MotWPSt 0;
BA_ "GenSigSendType" SG_ 958 HVACPmp_MotWPSt 1;
BA_ "GenSigStartValue" SG_ 958 HVACPmp_MotWPSt 0;
BA_ "GenSigTimeoutValue" SG_ 958 HVACPmp_MotWPSt 0;
BA_ "Remark" SG_ 958 HVACPmp_MotWPSt "";
BA_ "EventCommandSignal" SG_ 958 HVACPmp_MotWPErrCode 0;
BA_ "GatewayedSignals" SG_ 958 HVACPmp_MotWPErrCode 0;
BA_ "GenSigInactiveValue" SG_ 958 HVACPmp_MotWPErrCode 0;
BA_ "GenSigInvalidValue" SG_ 958 HVACPmp_MotWPErrCode 0;
BA_ "GenSigSendType" SG_ 958 HVACPmp_MotWPErrCode 1;
BA_ "GenSigStartValue" SG_ 958 HVACPmp_MotWPErrCode 0;
BA_ "GenSigTimeoutValue" SG_ 958 HVACPmp_MotWPErrCode 0;
BA_ "Remark" SG_ 958 HVACPmp_MotWPErrCode "";
BA_ "EventCommandSignal" SG_ 958 HVACSns_MotorInTVD 0;
BA_ "GatewayedSignals" SG_ 958 HVACSns_MotorInTVD 0;
BA_ "GenSigInactiveValue" SG_ 958 HVACSns_MotorInTVD 0;
BA_ "GenSigInvalidValue" SG_ 958 HVACSns_MotorInTVD 0;
BA_ "GenSigSendType" SG_ 958 HVACSns_MotorInTVD 1;
BA_ "GenSigStartValue" SG_ 958 HVACSns_MotorInTVD 0;
BA_ "GenSigTimeoutValue" SG_ 958 HVACSns_MotorInTVD 0;
BA_ "Remark" SG_ 958 HVACSns_MotorInTVD "";
BA_ "EventCommandSignal" SG_ 958 HVACSns_MotorInT 0;
BA_ "GatewayedSignals" SG_ 958 HVACSns_MotorInT 0;
BA_ "GenSigInactiveValue" SG_ 958 HVACSns_MotorInT 0;
BA_ "GenSigInvalidValue" SG_ 958 HVACSns_MotorInT 0;
BA_ "GenSigSendType" SG_ 958 HVACSns_MotorInT 1;
BA_ "GenSigStartValue" SG_ 958 HVACSns_MotorInT 130;
BA_ "GenSigTimeoutValue" SG_ 958 HVACSns_MotorInT 130;
BA_ "Remark" SG_ 958 HVACSns_MotorInT "";
BA_ "EventCommandSignal" SG_ 958 HVACPmp_MotWPActDuty 0;
BA_ "GatewayedSignals" SG_ 958 HVACPmp_MotWPActDuty 0;
BA_ "GenSigInactiveValue" SG_ 958 HVACPmp_MotWPActDuty 0;
BA_ "GenSigInvalidValue" SG_ 958 HVACPmp_MotWPActDuty 0;
BA_ "GenSigSendType" SG_ 958 HVACPmp_MotWPActDuty 1;
BA_ "GenSigStartValue" SG_ 958 HVACPmp_MotWPActDuty 0;
BA_ "GenSigTimeoutValue" SG_ 958 HVACPmp_MotWPActDuty 0;
BA_ "Remark" SG_ 958 HVACPmp_MotWPActDuty "";
BA_ "EventCommandSignal" SG_ 709 HVAC_AutoFogFlt 0;
BA_ "GatewayedSignals" SG_ 709 HVAC_AutoFogFlt 0;
BA_ "GenSigInactiveValue" SG_ 709 HVAC_AutoFogFlt 0;
BA_ "GenSigInvalidValue" SG_ 709 HVAC_AutoFogFlt 0;
BA_ "GenSigSendType" SG_ 709 HVAC_AutoFogFlt 1;
BA_ "GenSigStartValue" SG_ 709 HVAC_AutoFogFlt 0;
BA_ "GenSigTimeoutValue" SG_ 709 HVAC_AutoFogFlt 0;
BA_ "Remark" SG_ 709 HVAC_AutoFogFlt "";
BA_ "EventCommandSignal" SG_ 709 HVAC_AutoFogSts 0;
BA_ "GatewayedSignals" SG_ 709 HVAC_AutoFogSts 0;
BA_ "GenSigInactiveValue" SG_ 709 HVAC_AutoFogSts 0;
BA_ "GenSigInvalidValue" SG_ 709 HVAC_AutoFogSts 0;
BA_ "GenSigSendType" SG_ 709 HVAC_AutoFogSts 1;
BA_ "GenSigStartValue" SG_ 709 HVAC_AutoFogSts 0;
BA_ "GenSigTimeoutValue" SG_ 709 HVAC_AutoFogSts 0;
BA_ "Remark" SG_ 709 HVAC_AutoFogSts "";
BA_ "EventCommandSignal" SG_ 709 HVAC_CorrectedCabinTemp 0;
BA_ "GatewayedSignals" SG_ 709 HVAC_CorrectedCabinTemp 0;
BA_ "GenSigInactiveValue" SG_ 709 HVAC_CorrectedCabinTemp 0;
BA_ "GenSigInvalidValue" SG_ 709 HVAC_CorrectedCabinTemp 0;
BA_ "GenSigSendType" SG_ 709 HVAC_CorrectedCabinTemp 1;
BA_ "GenSigStartValue" SG_ 709 HVAC_CorrectedCabinTemp 120;
BA_ "GenSigTimeoutValue" SG_ 709 HVAC_CorrectedCabinTemp 120;
BA_ "Remark" SG_ 709 HVAC_CorrectedCabinTemp "";
BA_ "EventCommandSignal" SG_ 709 HVAC_CorrectedCabinTempVD 0;
BA_ "GatewayedSignals" SG_ 709 HVAC_CorrectedCabinTempVD 0;
BA_ "GenSigInactiveValue" SG_ 709 HVAC_CorrectedCabinTempVD 0;
BA_ "GenSigInvalidValue" SG_ 709 HVAC_CorrectedCabinTempVD 0;
BA_ "GenSigSendType" SG_ 709 HVAC_CorrectedCabinTempVD 1;
BA_ "GenSigStartValue" SG_ 709 HVAC_CorrectedCabinTempVD 0;
BA_ "GenSigTimeoutValue" SG_ 709 HVAC_CorrectedCabinTempVD 0;
BA_ "Remark" SG_ 709 HVAC_CorrectedCabinTempVD "";
BA_ "EventCommandSignal" SG_ 709 HVAC_CorrectedExterTemp 0;
BA_ "GatewayedSignals" SG_ 709 HVAC_CorrectedExterTemp 0;
BA_ "GenSigInactiveValue" SG_ 709 HVAC_CorrectedExterTemp 0;
BA_ "GenSigInvalidValue" SG_ 709 HVAC_CorrectedExterTemp 0;
BA_ "GenSigSendType" SG_ 709 HVAC_CorrectedExterTemp 1;
BA_ "GenSigStartValue" SG_ 709 HVAC_CorrectedExterTemp 120;
BA_ "GenSigTimeoutValue" SG_ 709 HVAC_CorrectedExterTemp 120;
BA_ "Remark" SG_ 709 HVAC_CorrectedExterTemp "";
BA_ "EventCommandSignal" SG_ 709 HVAC_CorrectedExterTempFault 0;
BA_ "GatewayedSignals" SG_ 709 HVAC_CorrectedExterTempFault 0;
BA_ "GenSigInactiveValue" SG_ 709 HVAC_CorrectedExterTempFault 0;
BA_ "GenSigInvalidValue" SG_ 709 HVAC_CorrectedExterTempFault 0;
BA_ "GenSigSendType" SG_ 709 HVAC_CorrectedExterTempFault 1;
BA_ "GenSigStartValue" SG_ 709 HVAC_CorrectedExterTempFault 0;
BA_ "GenSigTimeoutValue" SG_ 709 HVAC_CorrectedExterTempFault 1;
BA_ "Remark" SG_ 709 HVAC_CorrectedExterTempFault "";
BA_ "EventCommandSignal" SG_ 709 HVAC_CorrectedExterTempVD 0;
BA_ "GatewayedSignals" SG_ 709 HVAC_CorrectedExterTempVD 0;
BA_ "GenSigInactiveValue" SG_ 709 HVAC_CorrectedExterTempVD 0;
BA_ "GenSigInvalidValue" SG_ 709 HVAC_CorrectedExterTempVD 0;
BA_ "GenSigSendType" SG_ 709 HVAC_CorrectedExterTempVD 1;
BA_ "GenSigStartValue" SG_ 709 HVAC_CorrectedExterTempVD 0;
BA_ "GenSigTimeoutValue" SG_ 709 HVAC_CorrectedExterTempVD 0;
BA_ "Remark" SG_ 709 HVAC_CorrectedExterTempVD "";
BA_ "EventCommandSignal" SG_ 709 HVAC_MotWtrPmpSt 0;
BA_ "GatewayedSignals" SG_ 709 HVAC_MotWtrPmpSt 0;
BA_ "GenSigInactiveValue" SG_ 709 HVAC_MotWtrPmpSt 0;
BA_ "GenSigInvalidValue" SG_ 709 HVAC_MotWtrPmpSt 0;
BA_ "GenSigSendType" SG_ 709 HVAC_MotWtrPmpSt 1;
BA_ "GenSigStartValue" SG_ 709 HVAC_MotWtrPmpSt 0;
BA_ "GenSigTimeoutValue" SG_ 709 HVAC_MotWtrPmpSt 0;
BA_ "Remark" SG_ 709 HVAC_MotWtrPmpSt "";
BA_ "EventCommandSignal" SG_ 709 HVAC_RearDefrostSt 0;
BA_ "GatewayedSignals" SG_ 709 HVAC_RearDefrostSt 0;
BA_ "GenSigInactiveValue" SG_ 709 HVAC_RearDefrostSt 0;
BA_ "GenSigInvalidValue" SG_ 709 HVAC_RearDefrostSt 0;
BA_ "GenSigSendType" SG_ 709 HVAC_RearDefrostSt 1;
BA_ "GenSigStartValue" SG_ 709 HVAC_RearDefrostSt 0;
BA_ "GenSigTimeoutValue" SG_ 709 HVAC_RearDefrostSt 0;
BA_ "Remark" SG_ 709 HVAC_RearDefrostSt "";
BA_ "EventCommandSignal" SG_ 709 HVAC_WindExitMode 0;
BA_ "GatewayedSignals" SG_ 709 HVAC_WindExitMode 0;
BA_ "GenSigInactiveValue" SG_ 709 HVAC_WindExitMode 0;
BA_ "GenSigInvalidValue" SG_ 709 HVAC_WindExitMode 0;
BA_ "GenSigSendType" SG_ 709 HVAC_WindExitMode 1;
BA_ "GenSigStartValue" SG_ 709 HVAC_WindExitMode 0;
BA_ "GenSigTimeoutValue" SG_ 709 HVAC_WindExitMode 0;
BA_ "Remark" SG_ 709 HVAC_WindExitMode "";
BA_ "EventCommandSignal" SG_ 272 EMS_1_ICE_CRC 0;
BA_ "GatewayedSignals" SG_ 272 EMS_1_ICE_CRC 0;
BA_ "GenSigInactiveValue" SG_ 272 EMS_1_ICE_CRC 0;
BA_ "GenSigInvalidValue" SG_ 272 EMS_1_ICE_CRC 0;
BA_ "GenSigSendType" SG_ 272 EMS_1_ICE_CRC 1;
BA_ "GenSigStartValue" SG_ 272 EMS_1_ICE_CRC 0;
BA_ "GenSigTimeoutValue" SG_ 272 EMS_1_ICE_CRC 0;
BA_ "Remark" SG_ 272 EMS_1_ICE_CRC "涉及ID管理表";
BA_ "EventCommandSignal" SG_ 272 EMS_1_ICE_Counter 0;
BA_ "GatewayedSignals" SG_ 272 EMS_1_ICE_Counter 0;
BA_ "GenSigInactiveValue" SG_ 272 EMS_1_ICE_Counter 0;
BA_ "GenSigInvalidValue" SG_ 272 EMS_1_ICE_Counter 0;
BA_ "GenSigSendType" SG_ 272 EMS_1_ICE_Counter 1;
BA_ "GenSigStartValue" SG_ 272 EMS_1_ICE_Counter 0;
BA_ "GenSigTimeoutValue" SG_ 272 EMS_1_ICE_Counter 0;
BA_ "Remark" SG_ 272 EMS_1_ICE_Counter "涉及ID管理表";
BA_ "EventCommandSignal" SG_ 272 EMS_AccPedalVirtPst 0;
BA_ "GatewayedSignals" SG_ 272 EMS_AccPedalVirtPst 0;
BA_ "GenSigInactiveValue" SG_ 272 EMS_AccPedalVirtPst 0;
BA_ "GenSigInvalidValue" SG_ 272 EMS_AccPedalVirtPst 0;
BA_ "GenSigSendType" SG_ 272 EMS_AccPedalVirtPst 1;
BA_ "GenSigStartValue" SG_ 272 EMS_AccPedalVirtPst 0;
BA_ "GenSigTimeoutValue" SG_ 272 EMS_AccPedalVirtPst 0;
BA_ "Remark" SG_ 272 EMS_AccPedalVirtPst "涉及ID管理表";
BA_ "EventCommandSignal" SG_ 272 EMS_AccPedalVirtPstProtValue_ICE 0;
BA_ "GatewayedSignals" SG_ 272 EMS_AccPedalVirtPstProtValue_ICE 0;
BA_ "GenSigInactiveValue" SG_ 272 EMS_AccPedalVirtPstProtValue_ICE 0;
BA_ "GenSigInvalidValue" SG_ 272 EMS_AccPedalVirtPstProtValue_ICE 0;
BA_ "GenSigSendType" SG_ 272 EMS_AccPedalVirtPstProtValue_ICE 1;
BA_ "GenSigStartValue" SG_ 272 EMS_AccPedalVirtPstProtValue_ICE 0;
BA_ "GenSigTimeoutValue" SG_ 272 EMS_AccPedalVirtPstProtValue_ICE 0;
BA_ "Remark" SG_ 272 EMS_AccPedalVirtPstProtValue_ICE "涉及ID管理表";
BA_ "EventCommandSignal" SG_ 272 EMS_AccPedalVirtPstVD 0;
BA_ "GatewayedSignals" SG_ 272 EMS_AccPedalVirtPstVD 0;
BA_ "GenSigInactiveValue" SG_ 272 EMS_AccPedalVirtPstVD 0;
BA_ "GenSigInvalidValue" SG_ 272 EMS_AccPedalVirtPstVD 0;
BA_ "GenSigSendType" SG_ 272 EMS_AccPedalVirtPstVD 1;
BA_ "GenSigStartValue" SG_ 272 EMS_AccPedalVirtPstVD 0;
BA_ "GenSigTimeoutValue" SG_ 272 EMS_AccPedalVirtPstVD 0;
BA_ "Remark" SG_ 272 EMS_AccPedalVirtPstVD "涉及ID管理表";
BA_ "EventCommandSignal" SG_ 272 EMS_DriverPowerReq 0;
BA_ "GatewayedSignals" SG_ 272 EMS_DriverPowerReq 0;
BA_ "GenSigInactiveValue" SG_ 272 EMS_DriverPowerReq 0;
BA_ "GenSigInvalidValue" SG_ 272 EMS_DriverPowerReq 255;
BA_ "GenSigSendType" SG_ 272 EMS_DriverPowerReq 1;
BA_ "GenSigStartValue" SG_ 272 EMS_DriverPowerReq 0;
BA_ "GenSigTimeoutValue" SG_ 272 EMS_DriverPowerReq 0;
BA_ "Remark" SG_ 272 EMS_DriverPowerReq "涉及ID管理表";
BA_ "EventCommandSignal" SG_ 272 EMS_DriverPowerReqProtValue 0;
BA_ "GatewayedSignals" SG_ 272 EMS_DriverPowerReqProtValue 0;
BA_ "GenSigInactiveValue" SG_ 272 EMS_DriverPowerReqProtValue 0;
BA_ "GenSigInvalidValue" SG_ 272 EMS_DriverPowerReqProtValue 0;
BA_ "GenSigSendType" SG_ 272 EMS_DriverPowerReqProtValue 1;
BA_ "GenSigStartValue" SG_ 272 EMS_DriverPowerReqProtValue 0;
BA_ "GenSigTimeoutValue" SG_ 272 EMS_DriverPowerReqProtValue 0;
BA_ "Remark" SG_ 272 EMS_DriverPowerReqProtValue "涉及ID管理表";
BA_ "EventCommandSignal" SG_ 272 EMS_BrkPedalStVD_ICE 0;
BA_ "GatewayedSignals" SG_ 272 EMS_BrkPedalStVD_ICE 0;
BA_ "GenSigInactiveValue" SG_ 272 EMS_BrkPedalStVD_ICE 0;
BA_ "GenSigInvalidValue" SG_ 272 EMS_BrkPedalStVD_ICE 0;
BA_ "GenSigSendType" SG_ 272 EMS_BrkPedalStVD_ICE 1;
BA_ "GenSigStartValue" SG_ 272 EMS_BrkPedalStVD_ICE 0;
BA_ "GenSigTimeoutValue" SG_ 272 EMS_BrkPedalStVD_ICE 0;
BA_ "Remark" SG_ 272 EMS_BrkPedalStVD_ICE "涉及ID管理表";
BA_ "EventCommandSignal" SG_ 272 EMS_BrkPedalSt_ICE 0;
BA_ "GatewayedSignals" SG_ 272 EMS_BrkPedalSt_ICE 0;
BA_ "GenSigInactiveValue" SG_ 272 EMS_BrkPedalSt_ICE 0;
BA_ "GenSigInvalidValue" SG_ 272 EMS_BrkPedalSt_ICE 0;
BA_ "GenSigSendType" SG_ 272 EMS_BrkPedalSt_ICE 1;
BA_ "GenSigStartValue" SG_ 272 EMS_BrkPedalSt_ICE 0;
BA_ "GenSigTimeoutValue" SG_ 272 EMS_BrkPedalSt_ICE 0;
BA_ "Remark" SG_ 272 EMS_BrkPedalSt_ICE "涉及ID管理表";
BA_ "EventCommandSignal" SG_ 273 EMS_2_ICE_CRC 0;
BA_ "GatewayedSignals" SG_ 273 EMS_2_ICE_CRC 0;
BA_ "GenSigInactiveValue" SG_ 273 EMS_2_ICE_CRC 0;
BA_ "GenSigInvalidValue" SG_ 273 EMS_2_ICE_CRC 0;
BA_ "GenSigSendType" SG_ 273 EMS_2_ICE_CRC 1;
BA_ "GenSigStartValue" SG_ 273 EMS_2_ICE_CRC 0;
BA_ "GenSigTimeoutValue" SG_ 273 EMS_2_ICE_CRC 0;
BA_ "Remark" SG_ 273 EMS_2_ICE_CRC "涉及ID管理表";
BA_ "EventCommandSignal" SG_ 273 EMS_2_ICE_Counter 0;
BA_ "GatewayedSignals" SG_ 273 EMS_2_ICE_Counter 0;
BA_ "GenSigInactiveValue" SG_ 273 EMS_2_ICE_Counter 0;
BA_ "GenSigInvalidValue" SG_ 273 EMS_2_ICE_Counter 0;
BA_ "GenSigSendType" SG_ 273 EMS_2_ICE_Counter 1;
BA_ "GenSigStartValue" SG_ 273 EMS_2_ICE_Counter 0;
BA_ "GenSigTimeoutValue" SG_ 273 EMS_2_ICE_Counter 0;
BA_ "Remark" SG_ 273 EMS_2_ICE_Counter "涉及ID管理表";
BA_ "EventCommandSignal" SG_ 273 EMS_EngSt_ICE 0;
BA_ "GatewayedSignals" SG_ 273 EMS_EngSt_ICE 0;
BA_ "GenSigInactiveValue" SG_ 273 EMS_EngSt_ICE 0;
BA_ "GenSigInvalidValue" SG_ 273 EMS_EngSt_ICE 0;
BA_ "GenSigSendType" SG_ 273 EMS_EngSt_ICE 1;
BA_ "GenSigStartValue" SG_ 273 EMS_EngSt_ICE 0;
BA_ "GenSigTimeoutValue" SG_ 273 EMS_EngSt_ICE 0;
BA_ "Remark" SG_ 273 EMS_EngSt_ICE "涉及ID管理表";
BA_ "EventCommandSignal" SG_ 273 EMS_CruiseCtrlActive_ICE 0;
BA_ "GatewayedSignals" SG_ 273 EMS_CruiseCtrlActive_ICE 0;
BA_ "GenSigInactiveValue" SG_ 273 EMS_CruiseCtrlActive_ICE 0;
BA_ "GenSigInvalidValue" SG_ 273 EMS_CruiseCtrlActive_ICE 0;
BA_ "GenSigSendType" SG_ 273 EMS_CruiseCtrlActive_ICE 1;
BA_ "GenSigStartValue" SG_ 273 EMS_CruiseCtrlActive_ICE 0;
BA_ "GenSigTimeoutValue" SG_ 273 EMS_CruiseCtrlActive_ICE 0;
BA_ "Remark" SG_ 273 EMS_CruiseCtrlActive_ICE "涉及ID管理表";
BA_ "EventCommandSignal" SG_ 273 EMS_OverRideSt 0;
BA_ "GatewayedSignals" SG_ 273 EMS_OverRideSt 0;
BA_ "GenSigInactiveValue" SG_ 273 EMS_OverRideSt 0;
BA_ "GenSigInvalidValue" SG_ 273 EMS_OverRideSt 0;
BA_ "GenSigSendType" SG_ 273 EMS_OverRideSt 1;
BA_ "GenSigStartValue" SG_ 273 EMS_OverRideSt 0;
BA_ "GenSigTimeoutValue" SG_ 273 EMS_OverRideSt 0;
BA_ "Remark" SG_ 273 EMS_OverRideSt "涉及ID管理表";
BA_ "EventCommandSignal" SG_ 273 EMS_ACCButtInfo 0;
BA_ "GatewayedSignals" SG_ 273 EMS_ACCButtInfo 0;
BA_ "GenSigInactiveValue" SG_ 273 EMS_ACCButtInfo 0;
BA_ "GenSigInvalidValue" SG_ 273 EMS_ACCButtInfo 0;
BA_ "GenSigSendType" SG_ 273 EMS_ACCButtInfo 1;
BA_ "GenSigStartValue" SG_ 273 EMS_ACCButtInfo 0;
BA_ "GenSigTimeoutValue" SG_ 273 EMS_ACCButtInfo 0;
BA_ "Remark" SG_ 273 EMS_ACCButtInfo "涉及ID管理表";
BA_ "EventCommandSignal" SG_ 273 EMS_PtTqAvl 0;
BA_ "GatewayedSignals" SG_ 273 EMS_PtTqAvl 0;
BA_ "GenSigInactiveValue" SG_ 273 EMS_PtTqAvl 0;
BA_ "GenSigInvalidValue" SG_ 273 EMS_PtTqAvl 0;
BA_ "GenSigSendType" SG_ 273 EMS_PtTqAvl 1;
BA_ "GenSigStartValue" SG_ 273 EMS_PtTqAvl 0;
BA_ "GenSigTimeoutValue" SG_ 273 EMS_PtTqAvl 0;
BA_ "Remark" SG_ 273 EMS_PtTqAvl "涉及ID管理表";
BA_ "EventCommandSignal" SG_ 273 EMS_PtTqActvSts 0;
BA_ "GatewayedSignals" SG_ 273 EMS_PtTqActvSts 0;
BA_ "GenSigInactiveValue" SG_ 273 EMS_PtTqActvSts 0;
BA_ "GenSigInvalidValue" SG_ 273 EMS_PtTqActvSts 0;
BA_ "GenSigSendType" SG_ 273 EMS_PtTqActvSts 1;
BA_ "GenSigStartValue" SG_ 273 EMS_PtTqActvSts 0;
BA_ "GenSigTimeoutValue" SG_ 273 EMS_PtTqActvSts 0;
BA_ "Remark" SG_ 273 EMS_PtTqActvSts "涉及ID管理表";
BA_ "EventCommandSignal" SG_ 273 EMS_MinClutchTorq_ICE2 0;
BA_ "GatewayedSignals" SG_ 273 EMS_MinClutchTorq_ICE2 0;
BA_ "GenSigInactiveValue" SG_ 273 EMS_MinClutchTorq_ICE2 0;
BA_ "GenSigInvalidValue" SG_ 273 EMS_MinClutchTorq_ICE2 0;
BA_ "GenSigSendType" SG_ 273 EMS_MinClutchTorq_ICE2 1;
BA_ "GenSigStartValue" SG_ 273 EMS_MinClutchTorq_ICE2 45;
BA_ "GenSigTimeoutValue" SG_ 273 EMS_MinClutchTorq_ICE2 0;
BA_ "Remark" SG_ 273 EMS_MinClutchTorq_ICE2 "涉及ID管理表";
BA_ "EventCommandSignal" SG_ 273 EMS_MaxClutchTorq_ICE 0;
BA_ "GatewayedSignals" SG_ 273 EMS_MaxClutchTorq_ICE 0;
BA_ "GenSigInactiveValue" SG_ 273 EMS_MaxClutchTorq_ICE 0;
BA_ "GenSigInvalidValue" SG_ 273 EMS_MaxClutchTorq_ICE 0;
BA_ "GenSigSendType" SG_ 273 EMS_MaxClutchTorq_ICE 1;
BA_ "GenSigStartValue" SG_ 273 EMS_MaxClutchTorq_ICE 45;
BA_ "GenSigTimeoutValue" SG_ 273 EMS_MaxClutchTorq_ICE 0;
BA_ "Remark" SG_ 273 EMS_MaxClutchTorq_ICE "涉及ID管理表";
BA_ "EventCommandSignal" SG_ 273 EMS_MaxClutchTorqVD_ICE 0;
BA_ "GatewayedSignals" SG_ 273 EMS_MaxClutchTorqVD_ICE 0;
BA_ "GenSigInactiveValue" SG_ 273 EMS_MaxClutchTorqVD_ICE 0;
BA_ "GenSigInvalidValue" SG_ 273 EMS_MaxClutchTorqVD_ICE 0;
BA_ "GenSigSendType" SG_ 273 EMS_MaxClutchTorqVD_ICE 1;
BA_ "GenSigStartValue" SG_ 273 EMS_MaxClutchTorqVD_ICE 0;
BA_ "GenSigTimeoutValue" SG_ 273 EMS_MaxClutchTorqVD_ICE 0;
BA_ "Remark" SG_ 273 EMS_MaxClutchTorqVD_ICE "涉及ID管理表";
BA_ "EventCommandSignal" SG_ 273 EMS_MinClutchTorqVD_ICE 0;
BA_ "GatewayedSignals" SG_ 273 EMS_MinClutchTorqVD_ICE 0;
BA_ "GenSigInactiveValue" SG_ 273 EMS_MinClutchTorqVD_ICE 0;
BA_ "GenSigInvalidValue" SG_ 273 EMS_MinClutchTorqVD_ICE 0;
BA_ "GenSigSendType" SG_ 273 EMS_MinClutchTorqVD_ICE 1;
BA_ "GenSigStartValue" SG_ 273 EMS_MinClutchTorqVD_ICE 0;
BA_ "GenSigTimeoutValue" SG_ 273 EMS_MinClutchTorqVD_ICE 0;
BA_ "Remark" SG_ 273 EMS_MinClutchTorqVD_ICE "涉及ID管理表";
BA_ "EventCommandSignal" SG_ 273 EMS_EngSpd_ICE 0;
BA_ "GatewayedSignals" SG_ 273 EMS_EngSpd_ICE 0;
BA_ "GenSigInactiveValue" SG_ 273 EMS_EngSpd_ICE 0;
BA_ "GenSigInvalidValue" SG_ 273 EMS_EngSpd_ICE 0;
BA_ "GenSigSendType" SG_ 273 EMS_EngSpd_ICE 1;
BA_ "GenSigStartValue" SG_ 273 EMS_EngSpd_ICE 0;
BA_ "GenSigTimeoutValue" SG_ 273 EMS_EngSpd_ICE 0;
BA_ "Remark" SG_ 273 EMS_EngSpd_ICE "涉及ID管理表";
BA_ "EventCommandSignal" SG_ 273 EMS_EngSpdVD_ICE 0;
BA_ "GatewayedSignals" SG_ 273 EMS_EngSpdVD_ICE 0;
BA_ "GenSigInactiveValue" SG_ 273 EMS_EngSpdVD_ICE 0;
BA_ "GenSigInvalidValue" SG_ 273 EMS_EngSpdVD_ICE 0;
BA_ "GenSigSendType" SG_ 273 EMS_EngSpdVD_ICE 1;
BA_ "GenSigStartValue" SG_ 273 EMS_EngSpdVD_ICE 0;
BA_ "GenSigTimeoutValue" SG_ 273 EMS_EngSpdVD_ICE 0;
BA_ "Remark" SG_ 273 EMS_EngSpdVD_ICE "涉及ID管理表";
BA_ "EventCommandSignal" SG_ 274 EMS_3_ICE_CRC 0;
BA_ "GatewayedSignals" SG_ 274 EMS_3_ICE_CRC 0;
BA_ "GenSigInactiveValue" SG_ 274 EMS_3_ICE_CRC 0;
BA_ "GenSigInvalidValue" SG_ 274 EMS_3_ICE_CRC 0;
BA_ "GenSigSendType" SG_ 274 EMS_3_ICE_CRC 1;
BA_ "GenSigStartValue" SG_ 274 EMS_3_ICE_CRC 0;
BA_ "GenSigTimeoutValue" SG_ 274 EMS_3_ICE_CRC 0;
BA_ "Remark" SG_ 274 EMS_3_ICE_CRC "涉及ID管理表";
BA_ "EventCommandSignal" SG_ 274 EMS_3_ICE_Counter 0;
BA_ "GatewayedSignals" SG_ 274 EMS_3_ICE_Counter 0;
BA_ "GenSigInactiveValue" SG_ 274 EMS_3_ICE_Counter 0;
BA_ "GenSigInvalidValue" SG_ 274 EMS_3_ICE_Counter 0;
BA_ "GenSigSendType" SG_ 274 EMS_3_ICE_Counter 1;
BA_ "GenSigStartValue" SG_ 274 EMS_3_ICE_Counter 0;
BA_ "GenSigTimeoutValue" SG_ 274 EMS_3_ICE_Counter 0;
BA_ "Remark" SG_ 274 EMS_3_ICE_Counter "涉及ID管理表";
BA_ "EventCommandSignal" SG_ 274 EMS_ShiftLeverFailSt 0;
BA_ "GatewayedSignals" SG_ 274 EMS_ShiftLeverFailSt 0;
BA_ "GenSigInactiveValue" SG_ 274 EMS_ShiftLeverFailSt 0;
BA_ "GenSigInvalidValue" SG_ 274 EMS_ShiftLeverFailSt 0;
BA_ "GenSigSendType" SG_ 274 EMS_ShiftLeverFailSt 1;
BA_ "GenSigStartValue" SG_ 274 EMS_ShiftLeverFailSt 0;
BA_ "GenSigTimeoutValue" SG_ 274 EMS_ShiftLeverFailSt 0;
BA_ "Remark" SG_ 274 EMS_ShiftLeverFailSt "涉及ID管理表";
BA_ "EventCommandSignal" SG_ 274 EMS_APADriverInterv 0;
BA_ "GatewayedSignals" SG_ 274 EMS_APADriverInterv 0;
BA_ "GenSigInactiveValue" SG_ 274 EMS_APADriverInterv 0;
BA_ "GenSigInvalidValue" SG_ 274 EMS_APADriverInterv 0;
BA_ "GenSigSendType" SG_ 274 EMS_APADriverInterv 1;
BA_ "GenSigStartValue" SG_ 274 EMS_APADriverInterv 0;
BA_ "GenSigTimeoutValue" SG_ 274 EMS_APADriverInterv 0;
BA_ "Remark" SG_ 274 EMS_APADriverInterv "涉及ID管理表";
BA_ "EventCommandSignal" SG_ 274 EMS_ClutchTorqVD_ICE2 0;
BA_ "GatewayedSignals" SG_ 274 EMS_ClutchTorqVD_ICE2 0;
BA_ "GenSigInactiveValue" SG_ 274 EMS_ClutchTorqVD_ICE2 0;
BA_ "GenSigInvalidValue" SG_ 274 EMS_ClutchTorqVD_ICE2 0;
BA_ "GenSigSendType" SG_ 274 EMS_ClutchTorqVD_ICE2 1;
BA_ "GenSigStartValue" SG_ 274 EMS_ClutchTorqVD_ICE2 0;
BA_ "GenSigTimeoutValue" SG_ 274 EMS_ClutchTorqVD_ICE2 0;
BA_ "Remark" SG_ 274 EMS_ClutchTorqVD_ICE2 "涉及ID管理表";
BA_ "EventCommandSignal" SG_ 274 EMS_ClutchTorq_ICE2 0;
BA_ "GatewayedSignals" SG_ 274 EMS_ClutchTorq_ICE2 0;
BA_ "GenSigInactiveValue" SG_ 274 EMS_ClutchTorq_ICE2 0;
BA_ "GenSigInvalidValue" SG_ 274 EMS_ClutchTorq_ICE2 0;
BA_ "GenSigSendType" SG_ 274 EMS_ClutchTorq_ICE2 1;
BA_ "GenSigStartValue" SG_ 274 EMS_ClutchTorq_ICE2 45;
BA_ "GenSigTimeoutValue" SG_ 274 EMS_ClutchTorq_ICE2 45;
BA_ "Remark" SG_ 274 EMS_ClutchTorq_ICE2 "涉及ID管理表";
BA_ "EventCommandSignal" SG_ 274 EMS_GasPedalActPstforMRR_ICE 0;
BA_ "GatewayedSignals" SG_ 274 EMS_GasPedalActPstforMRR_ICE 0;
BA_ "GenSigInactiveValue" SG_ 274 EMS_GasPedalActPstforMRR_ICE 0;
BA_ "GenSigInvalidValue" SG_ 274 EMS_GasPedalActPstforMRR_ICE 0;
BA_ "GenSigSendType" SG_ 274 EMS_GasPedalActPstforMRR_ICE 1;
BA_ "GenSigStartValue" SG_ 274 EMS_GasPedalActPstforMRR_ICE 0;
BA_ "GenSigTimeoutValue" SG_ 274 EMS_GasPedalActPstforMRR_ICE 0;
BA_ "Remark" SG_ 274 EMS_GasPedalActPstforMRR_ICE "涉及ID管理表";
BA_ "EventCommandSignal" SG_ 274 EMS_GasPedalActPstforMRRVD_ICE 0;
BA_ "GatewayedSignals" SG_ 274 EMS_GasPedalActPstforMRRVD_ICE 0;
BA_ "GenSigInactiveValue" SG_ 274 EMS_GasPedalActPstforMRRVD_ICE 0;
BA_ "GenSigInvalidValue" SG_ 274 EMS_GasPedalActPstforMRRVD_ICE 0;
BA_ "GenSigSendType" SG_ 274 EMS_GasPedalActPstforMRRVD_ICE 1;
BA_ "GenSigStartValue" SG_ 274 EMS_GasPedalActPstforMRRVD_ICE 0;
BA_ "GenSigTimeoutValue" SG_ 274 EMS_GasPedalActPstforMRRVD_ICE 0;
BA_ "Remark" SG_ 274 EMS_GasPedalActPstforMRRVD_ICE "涉及ID管理表";
BA_ "EventCommandSignal" SG_ 274 EMS_GearShiftLeverPstReq_ICE 0;
BA_ "GatewayedSignals" SG_ 274 EMS_GearShiftLeverPstReq_ICE 0;
BA_ "GenSigInactiveValue" SG_ 274 EMS_GearShiftLeverPstReq_ICE 0;
BA_ "GenSigInvalidValue" SG_ 274 EMS_GearShiftLeverPstReq_ICE 0;
BA_ "GenSigSendType" SG_ 274 EMS_GearShiftLeverPstReq_ICE 1;
BA_ "GenSigStartValue" SG_ 274 EMS_GearShiftLeverPstReq_ICE 0;
BA_ "GenSigTimeoutValue" SG_ 274 EMS_GearShiftLeverPstReq_ICE 0;
BA_ "Remark" SG_ 274 EMS_GearShiftLeverPstReq_ICE "涉及ID管理表";
BA_ "EventCommandSignal" SG_ 274 EMS_ClutchTorqTargetWOTCUVD 0;
BA_ "GatewayedSignals" SG_ 274 EMS_ClutchTorqTargetWOTCUVD 0;
BA_ "GenSigInactiveValue" SG_ 274 EMS_ClutchTorqTargetWOTCUVD 0;
BA_ "GenSigInvalidValue" SG_ 274 EMS_ClutchTorqTargetWOTCUVD 0;
BA_ "GenSigSendType" SG_ 274 EMS_ClutchTorqTargetWOTCUVD 1;
BA_ "GenSigStartValue" SG_ 274 EMS_ClutchTorqTargetWOTCUVD 0;
BA_ "GenSigTimeoutValue" SG_ 274 EMS_ClutchTorqTargetWOTCUVD 0;
BA_ "Remark" SG_ 274 EMS_ClutchTorqTargetWOTCUVD "涉及ID管理表";
BA_ "EventCommandSignal" SG_ 274 EMS_ClutchTorqTargetWOTCU 0;
BA_ "GatewayedSignals" SG_ 274 EMS_ClutchTorqTargetWOTCU 0;
BA_ "GenSigInactiveValue" SG_ 274 EMS_ClutchTorqTargetWOTCU 0;
BA_ "GenSigInvalidValue" SG_ 274 EMS_ClutchTorqTargetWOTCU 0;
BA_ "GenSigSendType" SG_ 274 EMS_ClutchTorqTargetWOTCU 1;
BA_ "GenSigStartValue" SG_ 274 EMS_ClutchTorqTargetWOTCU 45;
BA_ "GenSigTimeoutValue" SG_ 274 EMS_ClutchTorqTargetWOTCU 0;
BA_ "Remark" SG_ 274 EMS_ClutchTorqTargetWOTCU "涉及ID管理表";
BA_ "EventCommandSignal" SG_ 274 EMS_GearShiftAvl 0;
BA_ "GatewayedSignals" SG_ 274 EMS_GearShiftAvl 0;
BA_ "GenSigInactiveValue" SG_ 274 EMS_GearShiftAvl 0;
BA_ "GenSigInvalidValue" SG_ 274 EMS_GearShiftAvl 0;
BA_ "GenSigSendType" SG_ 274 EMS_GearShiftAvl 1;
BA_ "GenSigStartValue" SG_ 274 EMS_GearShiftAvl 0;
BA_ "GenSigTimeoutValue" SG_ 274 EMS_GearShiftAvl 0;
BA_ "Remark" SG_ 274 EMS_GearShiftAvl "涉及ID管理表";
BA_ "EventCommandSignal" SG_ 274 EMS_ClutchTorqDriverReqVD_ICE 0;
BA_ "GatewayedSignals" SG_ 274 EMS_ClutchTorqDriverReqVD_ICE 0;
BA_ "GenSigInactiveValue" SG_ 274 EMS_ClutchTorqDriverReqVD_ICE 0;
BA_ "GenSigInvalidValue" SG_ 274 EMS_ClutchTorqDriverReqVD_ICE 0;
BA_ "GenSigSendType" SG_ 274 EMS_ClutchTorqDriverReqVD_ICE 1;
BA_ "GenSigStartValue" SG_ 274 EMS_ClutchTorqDriverReqVD_ICE 0;
BA_ "GenSigTimeoutValue" SG_ 274 EMS_ClutchTorqDriverReqVD_ICE 0;
BA_ "Remark" SG_ 274 EMS_ClutchTorqDriverReqVD_ICE "涉及ID管理表";
BA_ "EventCommandSignal" SG_ 274 EMS_ClutchTorqDriverReq_ICE 0;
BA_ "GatewayedSignals" SG_ 274 EMS_ClutchTorqDriverReq_ICE 0;
BA_ "GenSigInactiveValue" SG_ 274 EMS_ClutchTorqDriverReq_ICE 0;
BA_ "GenSigInvalidValue" SG_ 274 EMS_ClutchTorqDriverReq_ICE 0;
BA_ "GenSigSendType" SG_ 274 EMS_ClutchTorqDriverReq_ICE 1;
BA_ "GenSigStartValue" SG_ 274 EMS_ClutchTorqDriverReq_ICE 45;
BA_ "GenSigTimeoutValue" SG_ 274 EMS_ClutchTorqDriverReq_ICE 45;
BA_ "Remark" SG_ 274 EMS_ClutchTorqDriverReq_ICE "涉及ID管理表";
BA_ "EventCommandSignal" SG_ 274 EMS_EngFrictionTorqVD_ICE 0;
BA_ "GatewayedSignals" SG_ 274 EMS_EngFrictionTorqVD_ICE 0;
BA_ "GenSigInactiveValue" SG_ 274 EMS_EngFrictionTorqVD_ICE 0;
BA_ "GenSigInvalidValue" SG_ 274 EMS_EngFrictionTorqVD_ICE 0;
BA_ "GenSigSendType" SG_ 274 EMS_EngFrictionTorqVD_ICE 1;
BA_ "GenSigStartValue" SG_ 274 EMS_EngFrictionTorqVD_ICE 0;
BA_ "GenSigTimeoutValue" SG_ 274 EMS_EngFrictionTorqVD_ICE 0;
BA_ "Remark" SG_ 274 EMS_EngFrictionTorqVD_ICE "涉及ID管理表";
BA_ "EventCommandSignal" SG_ 274 EMS_EngFrictionTorq_ICE 0;
BA_ "GatewayedSignals" SG_ 274 EMS_EngFrictionTorq_ICE 0;
BA_ "GenSigInactiveValue" SG_ 274 EMS_EngFrictionTorq_ICE 0;
BA_ "GenSigInvalidValue" SG_ 274 EMS_EngFrictionTorq_ICE 0;
BA_ "GenSigSendType" SG_ 274 EMS_EngFrictionTorq_ICE 1;
BA_ "GenSigStartValue" SG_ 274 EMS_EngFrictionTorq_ICE 45;
BA_ "GenSigTimeoutValue" SG_ 274 EMS_EngFrictionTorq_ICE 0;
BA_ "Remark" SG_ 274 EMS_EngFrictionTorq_ICE "涉及ID管理表";
BA_ "EventCommandSignal" SG_ 280 TCU_2_ICE_CRC 0;
BA_ "GatewayedSignals" SG_ 280 TCU_2_ICE_CRC 0;
BA_ "GenSigInactiveValue" SG_ 280 TCU_2_ICE_CRC 0;
BA_ "GenSigInvalidValue" SG_ 280 TCU_2_ICE_CRC 0;
BA_ "GenSigSendType" SG_ 280 TCU_2_ICE_CRC 1;
BA_ "GenSigStartValue" SG_ 280 TCU_2_ICE_CRC 0;
BA_ "GenSigTimeoutValue" SG_ 280 TCU_2_ICE_CRC 0;
BA_ "Remark" SG_ 280 TCU_2_ICE_CRC "涉及ID管理表";
BA_ "EventCommandSignal" SG_ 280 TCU_2_ICE_Counter 0;
BA_ "GatewayedSignals" SG_ 280 TCU_2_ICE_Counter 0;
BA_ "GenSigInactiveValue" SG_ 280 TCU_2_ICE_Counter 0;
BA_ "GenSigInvalidValue" SG_ 280 TCU_2_ICE_Counter 0;
BA_ "GenSigSendType" SG_ 280 TCU_2_ICE_Counter 1;
BA_ "GenSigStartValue" SG_ 280 TCU_2_ICE_Counter 0;
BA_ "GenSigTimeoutValue" SG_ 280 TCU_2_ICE_Counter 0;
BA_ "Remark" SG_ 280 TCU_2_ICE_Counter "涉及ID管理表";
BA_ "EventCommandSignal" SG_ 280 TCU_GearForDisp_ICE 0;
BA_ "GatewayedSignals" SG_ 280 TCU_GearForDisp_ICE 0;
BA_ "GenSigInactiveValue" SG_ 280 TCU_GearForDisp_ICE 0;
BA_ "GenSigInvalidValue" SG_ 280 TCU_GearForDisp_ICE 0;
BA_ "GenSigSendType" SG_ 280 TCU_GearForDisp_ICE 1;
BA_ "GenSigStartValue" SG_ 280 TCU_GearForDisp_ICE 0;
BA_ "GenSigTimeoutValue" SG_ 280 TCU_GearForDisp_ICE 0;
BA_ "Remark" SG_ 280 TCU_GearForDisp_ICE "涉及ID管理表";
BA_ "EventCommandSignal" SG_ 280 TCU_TargetGearSt_ICE 0;
BA_ "GatewayedSignals" SG_ 280 TCU_TargetGearSt_ICE 0;
BA_ "GenSigInactiveValue" SG_ 280 TCU_TargetGearSt_ICE 0;
BA_ "GenSigInvalidValue" SG_ 280 TCU_TargetGearSt_ICE 0;
BA_ "GenSigSendType" SG_ 280 TCU_TargetGearSt_ICE 1;
BA_ "GenSigStartValue" SG_ 280 TCU_TargetGearSt_ICE 13;
BA_ "GenSigTimeoutValue" SG_ 280 TCU_TargetGearSt_ICE 0;
BA_ "Remark" SG_ 280 TCU_TargetGearSt_ICE "涉及ID管理表";
BA_ "EventCommandSignal" SG_ 280 TCU_TargetGearStVD_ICE 0;
BA_ "GatewayedSignals" SG_ 280 TCU_TargetGearStVD_ICE 0;
BA_ "GenSigInactiveValue" SG_ 280 TCU_TargetGearStVD_ICE 0;
BA_ "GenSigInvalidValue" SG_ 280 TCU_TargetGearStVD_ICE 0;
BA_ "GenSigSendType" SG_ 280 TCU_TargetGearStVD_ICE 1;
BA_ "GenSigStartValue" SG_ 280 TCU_TargetGearStVD_ICE 0;
BA_ "GenSigTimeoutValue" SG_ 280 TCU_TargetGearStVD_ICE 0;
BA_ "Remark" SG_ 280 TCU_TargetGearStVD_ICE "涉及ID管理表";
BA_ "EventCommandSignal" SG_ 280 TCU_CurrentGearStVD_ICE 0;
BA_ "GatewayedSignals" SG_ 280 TCU_CurrentGearStVD_ICE 0;
BA_ "GenSigInactiveValue" SG_ 280 TCU_CurrentGearStVD_ICE 0;
BA_ "GenSigInvalidValue" SG_ 280 TCU_CurrentGearStVD_ICE 0;
BA_ "GenSigSendType" SG_ 280 TCU_CurrentGearStVD_ICE 1;
BA_ "GenSigStartValue" SG_ 280 TCU_CurrentGearStVD_ICE 0;
BA_ "GenSigTimeoutValue" SG_ 280 TCU_CurrentGearStVD_ICE 0;
BA_ "Remark" SG_ 280 TCU_CurrentGearStVD_ICE "涉及ID管理表";
BA_ "EventCommandSignal" SG_ 280 TCU_CurrentGearSt_ICE 0;
BA_ "GatewayedSignals" SG_ 280 TCU_CurrentGearSt_ICE 0;
BA_ "GenSigInactiveValue" SG_ 280 TCU_CurrentGearSt_ICE 0;
BA_ "GenSigInvalidValue" SG_ 280 TCU_CurrentGearSt_ICE 0;
BA_ "GenSigSendType" SG_ 280 TCU_CurrentGearSt_ICE 1;
BA_ "GenSigStartValue" SG_ 280 TCU_CurrentGearSt_ICE 13;
BA_ "GenSigTimeoutValue" SG_ 280 TCU_CurrentGearSt_ICE 0;
BA_ "Remark" SG_ 280 TCU_CurrentGearSt_ICE "涉及ID管理表";
BA_ "EventCommandSignal" SG_ 284 ADC_1_ICE_CRC 0;
BA_ "GatewayedSignals" SG_ 284 ADC_1_ICE_CRC 0;
BA_ "GenSigInactiveValue" SG_ 284 ADC_1_ICE_CRC 0;
BA_ "GenSigInvalidValue" SG_ 284 ADC_1_ICE_CRC 0;
BA_ "GenSigSendType" SG_ 284 ADC_1_ICE_CRC 1;
BA_ "GenSigStartValue" SG_ 284 ADC_1_ICE_CRC 0;
BA_ "GenSigTimeoutValue" SG_ 284 ADC_1_ICE_CRC 0;
BA_ "Remark" SG_ 284 ADC_1_ICE_CRC "";
BA_ "EventCommandSignal" SG_ 284 ADC_1_ICE_Counter 0;
BA_ "GatewayedSignals" SG_ 284 ADC_1_ICE_Counter 0;
BA_ "GenSigInactiveValue" SG_ 284 ADC_1_ICE_Counter 0;
BA_ "GenSigInvalidValue" SG_ 284 ADC_1_ICE_Counter 0;
BA_ "GenSigSendType" SG_ 284 ADC_1_ICE_Counter 1;
BA_ "GenSigStartValue" SG_ 284 ADC_1_ICE_Counter 0;
BA_ "GenSigTimeoutValue" SG_ 284 ADC_1_ICE_Counter 0;
BA_ "Remark" SG_ 284 ADC_1_ICE_Counter "";
BA_ "EventCommandSignal" SG_ 284 ADC_ACCMode_C_ICE 0;
BA_ "GatewayedSignals" SG_ 284 ADC_ACCMode_C_ICE 0;
BA_ "GenSigInactiveValue" SG_ 284 ADC_ACCMode_C_ICE 0;
BA_ "GenSigInvalidValue" SG_ 284 ADC_ACCMode_C_ICE 0;
BA_ "GenSigSendType" SG_ 284 ADC_ACCMode_C_ICE 1;
BA_ "GenSigStartValue" SG_ 284 ADC_ACCMode_C_ICE 1;
BA_ "GenSigTimeoutValue" SG_ 284 ADC_ACCMode_C_ICE 0;
BA_ "Remark" SG_ 284 ADC_ACCMode_C_ICE "";
BA_ "EventCommandSignal" SG_ 284 ADC_ActTrqReqVD_ICE 0;
BA_ "GatewayedSignals" SG_ 284 ADC_ActTrqReqVD_ICE 0;
BA_ "GenSigInactiveValue" SG_ 284 ADC_ActTrqReqVD_ICE 0;
BA_ "GenSigInvalidValue" SG_ 284 ADC_ActTrqReqVD_ICE 0;
BA_ "GenSigSendType" SG_ 284 ADC_ActTrqReqVD_ICE 1;
BA_ "GenSigStartValue" SG_ 284 ADC_ActTrqReqVD_ICE 0;
BA_ "GenSigTimeoutValue" SG_ 284 ADC_ActTrqReqVD_ICE 0;
BA_ "Remark" SG_ 284 ADC_ActTrqReqVD_ICE "";
BA_ "EventCommandSignal" SG_ 284 ADC_ActTrqReqEnable_ICE 0;
BA_ "GatewayedSignals" SG_ 284 ADC_ActTrqReqEnable_ICE 0;
BA_ "GenSigInactiveValue" SG_ 284 ADC_ActTrqReqEnable_ICE 0;
BA_ "GenSigInvalidValue" SG_ 284 ADC_ActTrqReqEnable_ICE 0;
BA_ "GenSigSendType" SG_ 284 ADC_ActTrqReqEnable_ICE 1;
BA_ "GenSigStartValue" SG_ 284 ADC_ActTrqReqEnable_ICE 0;
BA_ "GenSigTimeoutValue" SG_ 284 ADC_ActTrqReqEnable_ICE 0;
BA_ "Remark" SG_ 284 ADC_ActTrqReqEnable_ICE "";
BA_ "EventCommandSignal" SG_ 284 ADC_FctSts_ICE 0;
BA_ "GatewayedSignals" SG_ 284 ADC_FctSts_ICE 0;
BA_ "GenSigInactiveValue" SG_ 284 ADC_FctSts_ICE 0;
BA_ "GenSigInvalidValue" SG_ 284 ADC_FctSts_ICE 0;
BA_ "GenSigSendType" SG_ 284 ADC_FctSts_ICE 1;
BA_ "GenSigStartValue" SG_ 284 ADC_FctSts_ICE 0;
BA_ "GenSigTimeoutValue" SG_ 284 ADC_FctSts_ICE 0;
BA_ "Remark" SG_ 284 ADC_FctSts_ICE "";
BA_ "EventCommandSignal" SG_ 284 ADC_ActTrqReqToEMS_ICE 0;
BA_ "GatewayedSignals" SG_ 284 ADC_ActTrqReqToEMS_ICE 0;
BA_ "GenSigInactiveValue" SG_ 284 ADC_ActTrqReqToEMS_ICE 0;
BA_ "GenSigInvalidValue" SG_ 284 ADC_ActTrqReqToEMS_ICE 0;
BA_ "GenSigSendType" SG_ 284 ADC_ActTrqReqToEMS_ICE 1;
BA_ "GenSigStartValue" SG_ 284 ADC_ActTrqReqToEMS_ICE 0;
BA_ "GenSigTimeoutValue" SG_ 284 ADC_ActTrqReqToEMS_ICE 0;
BA_ "Remark" SG_ 284 ADC_ActTrqReqToEMS_ICE "";
BA_ "EventCommandSignal" SG_ 284 ADC_DrvMod_ICE 0;
BA_ "GatewayedSignals" SG_ 284 ADC_DrvMod_ICE 0;
BA_ "GenSigInactiveValue" SG_ 284 ADC_DrvMod_ICE 0;
BA_ "GenSigInvalidValue" SG_ 284 ADC_DrvMod_ICE 0;
BA_ "GenSigSendType" SG_ 284 ADC_DrvMod_ICE 1;
BA_ "GenSigStartValue" SG_ 284 ADC_DrvMod_ICE 0;
BA_ "GenSigTimeoutValue" SG_ 284 ADC_DrvMod_ICE 0;
BA_ "Remark" SG_ 284 ADC_DrvMod_ICE "";
BA_ "EventCommandSignal" SG_ 284 ADC_PAAGrarLvlReq_ICE 0;
BA_ "GatewayedSignals" SG_ 284 ADC_PAAGrarLvlReq_ICE 0;
BA_ "GenSigInactiveValue" SG_ 284 ADC_PAAGrarLvlReq_ICE 0;
BA_ "GenSigInvalidValue" SG_ 284 ADC_PAAGrarLvlReq_ICE 0;
BA_ "GenSigSendType" SG_ 284 ADC_PAAGrarLvlReq_ICE 1;
BA_ "GenSigStartValue" SG_ 284 ADC_PAAGrarLvlReq_ICE 0;
BA_ "GenSigTimeoutValue" SG_ 284 ADC_PAAGrarLvlReq_ICE 0;
BA_ "Remark" SG_ 284 ADC_PAAGrarLvlReq_ICE "";
BA_ "EventCommandSignal" SG_ 284 ADC_PAAGrarLvlReqEnable_ICE 0;
BA_ "GatewayedSignals" SG_ 284 ADC_PAAGrarLvlReqEnable_ICE 0;
BA_ "GenSigInactiveValue" SG_ 284 ADC_PAAGrarLvlReqEnable_ICE 0;
BA_ "GenSigInvalidValue" SG_ 284 ADC_PAAGrarLvlReqEnable_ICE 0;
BA_ "GenSigSendType" SG_ 284 ADC_PAAGrarLvlReqEnable_ICE 1;
BA_ "GenSigStartValue" SG_ 284 ADC_PAAGrarLvlReqEnable_ICE 0;
BA_ "GenSigTimeoutValue" SG_ 284 ADC_PAAGrarLvlReqEnable_ICE 0;
BA_ "Remark" SG_ 284 ADC_PAAGrarLvlReqEnable_ICE "";
BA_ "EventCommandSignal" SG_ 284 ADC_TarGearReqVld_ICE 0;
BA_ "GatewayedSignals" SG_ 284 ADC_TarGearReqVld_ICE 0;
BA_ "GenSigInactiveValue" SG_ 284 ADC_TarGearReqVld_ICE 0;
BA_ "GenSigInvalidValue" SG_ 284 ADC_TarGearReqVld_ICE 0;
BA_ "GenSigSendType" SG_ 284 ADC_TarGearReqVld_ICE 1;
BA_ "GenSigStartValue" SG_ 284 ADC_TarGearReqVld_ICE 0;
BA_ "GenSigTimeoutValue" SG_ 284 ADC_TarGearReqVld_ICE 0;
BA_ "Remark" SG_ 284 ADC_TarGearReqVld_ICE "";
BA_ "EventCommandSignal" SG_ 284 ADC_DrvTarTqMod_ICE 0;
BA_ "GatewayedSignals" SG_ 284 ADC_DrvTarTqMod_ICE 0;
BA_ "GenSigInactiveValue" SG_ 284 ADC_DrvTarTqMod_ICE 0;
BA_ "GenSigInvalidValue" SG_ 284 ADC_DrvTarTqMod_ICE 0;
BA_ "GenSigSendType" SG_ 284 ADC_DrvTarTqMod_ICE 1;
BA_ "GenSigStartValue" SG_ 284 ADC_DrvTarTqMod_ICE 0;
BA_ "GenSigTimeoutValue" SG_ 284 ADC_DrvTarTqMod_ICE 0;
BA_ "Remark" SG_ 284 ADC_DrvTarTqMod_ICE "";
BA_ "EventCommandSignal" SG_ 1174 ADC_BigData 0;
BA_ "GatewayedSignals" SG_ 1174 ADC_BigData 0;
BA_ "GenSigInactiveValue" SG_ 1174 ADC_BigData 0;
BA_ "GenSigInvalidValue" SG_ 1174 ADC_BigData 0;
BA_ "GenSigSendType" SG_ 1174 ADC_BigData 1;
BA_ "GenSigStartValue" SG_ 1174 ADC_BigData 0;
BA_ "GenSigTimeoutValue" SG_ 1174 ADC_BigData 0;
BA_ "Remark" SG_ 1174 ADC_BigData "";
VAL_ 704 IPS_DCDCModeSt 7 "Failure;" 3 "Active - Buck Mode;" 2 "Connected (HV is active);" 1 "Disconnected;" 0 "Init;"  ;
VAL_ 794 LBMSAD_SOFVD 0 "Invalid" 1 "Valid"  ;
VAL_ 794 LBMSAD_SOFEN 0 "Keep to the side parking False,Original lane parking False" 1 "Keep to the side parking True,Original lane parking False" 2 "Keep to the side parking False,Original lane parking True" 3 "Keep to the side parking True,Original lane parking True"  ;
VAL_ 958 HVACSns_MotorInTVD 0 "Invalid" 1 "Valid"  ;
VAL_ 709 HVAC_AutoFogFlt 0 "No Fault" 1 "Fault"  ;
VAL_ 709 HVAC_AutoFogSts 0 "Not Active" 1 "Active"  ;
VAL_ 709 HVAC_CorrectedCabinTempVD 0 "Not valid" 1 "Valid"  ;
VAL_ 709 HVAC_CorrectedExterTempFault 0 "Normal" 1 "circuit short to ground" 2 "circuit short to battery or open" 3 "reserve"  ;
VAL_ 709 HVAC_CorrectedExterTempVD 0 "Not valid" 1 "Valid"  ;
VAL_ 709 HVAC_RearDefrostSt 0 "Not acitve" 1 "Active"  ;
VAL_ 709 HVAC_WindExitMode 0 "Invalid" 1 "Face" 2 "Face/Foot" 3 "Foot" 4 "Foot/Defrost" 5 "Defrost" 6 "Face/DEF" 7 "Face/Foot/DEF"  ;
VAL_ 272 EMS_AccPedalVirtPstProtValue_ICE 14 "(EMS_6_MsgCounter+EMS_AccPedalPst+EMS_AccPedalPstVD) XOR (0xFF)"  ;
VAL_ 272 EMS_AccPedalVirtPstVD 0 "Not valid" 1 "Valid"  ;
VAL_ 272 EMS_DriverPowerReqProtValue 14 "(EMS_DriverPowerReq+EMS_6_MsgCounter) XOR 0xFF"  ;
VAL_ 272 EMS_BrkPedalStVD_ICE 0 "Not valid" 1 "Valid"  ;
VAL_ 272 EMS_BrkPedalSt_ICE 0 "Not pressed" 1 "Pressed"  ;
VAL_ 273 EMS_EngSt_ICE 0 "Not run" 1 "Run"  ;
VAL_ 273 EMS_CruiseCtrlActive_ICE 0 "OFF" 1 "Active" 2 "Standby" 3 "Invalid"  ;
VAL_ 273 EMS_OverRideSt 0 "Off" 1 "On"  ;
VAL_ 273 EMS_ACCButtInfo 0 "not press" 1 "press" 0 "not press" 1 "press" 0 "not press" 1 "press" 0 "not press" 1 "press" 0 "not press" 1 "press" 0 "Normal" 1 "Abnormal"  ;
VAL_ 273 EMS_PtTqActvSts 0 "Not response" 1 "Response"  ;
VAL_ 273 EMS_MaxClutchTorqVD_ICE 0 "Invalid" 1 "Valid"  ;
VAL_ 273 EMS_MinClutchTorqVD_ICE 0 "Invalid" 1 "Valid"  ;
VAL_ 273 EMS_EngSpdVD_ICE 0 "Invalid" 1 "Valid"  ;
VAL_ 274 EMS_ShiftLeverFailSt 0 "Not fail" 1 "Fail"  ;
VAL_ 274 EMS_APADriverInterv 0 "with not intervention" 1 "with intervention"  ;
VAL_ 274 EMS_ClutchTorqVD_ICE2 0 "Invalid" 1 "Valid"  ;
VAL_ 274 EMS_GasPedalActPstforMRRVD_ICE 0 "Invalid" 1 "Valid"  ;
VAL_ 274 EMS_GearShiftLeverPstReq_ICE 0 "Invalid" 1 "P" 2 "R" 3 "N" 4 "D" 5 "D+" 6 "D-" 7 "S" 8 "M" 9 "M+" 10 "M-" 11 "Default" 12 "Not used" 13 "Not used" 14 "Not used" 15 "Not used"  ;
VAL_ 274 EMS_ClutchTorqTargetWOTCUVD 0 "Invalid" 1 "Valid"  ;
VAL_ 274 EMS_GearShiftAvl 0 "Not available" 1 "Available"  ;
VAL_ 274 EMS_ClutchTorqDriverReqVD_ICE 0 "Invalid" 1 "Valid"  ;
VAL_ 274 EMS_EngFrictionTorqVD_ICE 0 "Invalid" 1 "Valid"  ;
VAL_ 280 TCU_GearForDisp_ICE 0 "Invalid" 1 "1st gear" 2 "2nd gear" 3 "3rd gear" 4 "4th gear" 5 "5th gear" 6 "6th gear" 7 "7th gear" 8 "8th gear" 9 "9th gear" 10 "No connection area" 11 "Sport gear" 12 "Drive gear" 13 "Park gear" 14 "Reverse gear" 15 "Neutral gear"  ;
VAL_ 280 TCU_TargetGearSt_ICE 0 "Invalid" 1 "1st gear" 2 "2nd gear" 3 "3rd gear" 4 "4th gear" 5 "5th gear" 6 "6th gear" 7 "7th gear" 8 "8th gear" 9 "Not used" 10 "Not used" 11 "Not used" 12 "Not used" 13 "Park gear" 14 "Reverse gear" 15 "Neutral gear"  ;
VAL_ 280 TCU_TargetGearStVD_ICE 0 "Not Valid" 1 "Valid"  ;
VAL_ 280 TCU_CurrentGearStVD_ICE 0 "Not Valid" 1 "Valid"  ;
VAL_ 280 TCU_CurrentGearSt_ICE 0 "Invalid" 1 "1st gear" 2 "2nd gear" 3 "3rd gear" 4 "4th gear" 5 "5th gear" 6 "6th gear" 7 "7th gear" 8 "8th gear" 9 "Not used" 10 "Not used" 11 "Not used" 12 "Not used" 13 "Park gear" 14 "Reverse gear" 15 "Neutral gear"  ;
VAL_ 284 ADC_ACCMode_C_ICE 0 "Failure" 1 "Passive mode" 2 "Standby mode" 3 "Active control mode" 4 "Brake only mode" 5 "Override" 6 "Standwait" 7 "Standactive" 8 "Not used" 9 "Not used" 10 "Not used" 11 "Not used" 12 "Not used" 13 "Not used" 14 "Not used" 15 "Not used"  ;
VAL_ 284 ADC_ActTrqReqVD_ICE 0 "invalid" 1 "valid"  ;
VAL_ 284 ADC_ActTrqReqEnable_ICE 0 "Not valid" 1 "Valid"  ;
VAL_ 284 ADC_FctSts_ICE 0 "Off" 1 "On"  ;
VAL_ 284 ADC_DrvMod_ICE 0 "no request" 1 "Cruise function" 2 "Parking function" 3 "Reserved"  ;
VAL_ 284 ADC_PAAGrarLvlReq_ICE 0 "No Request" 1 "Park" 2 "Reversed" 3 "Neutral" 4 "Drive" 5 "Reversed" 6 "Reversed" 7 "Reversed"  ;
VAL_ 284 ADC_PAAGrarLvlReqEnable_ICE 0 "No request" 1 "Gear shift request"  ;
VAL_ 284 ADC_TarGearReqVld_ICE 0 "Invalid" 1 "Valid"  ;
VAL_ 284 ADC_DrvTarTqMod_ICE 0 "Override mode" 1 "Inhibit mode" 2 "reserved" 3 "reserved"  ;
